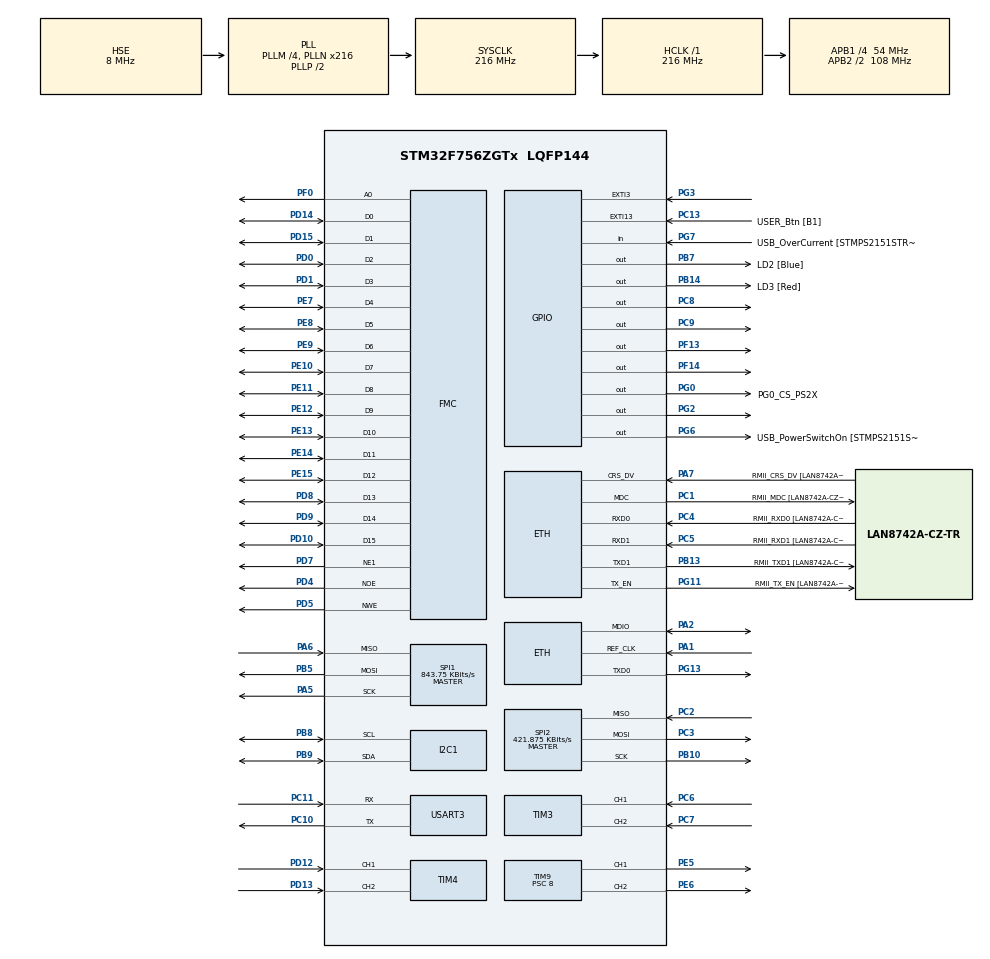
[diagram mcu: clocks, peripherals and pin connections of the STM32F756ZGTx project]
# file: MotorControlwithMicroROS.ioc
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CORTEX_M7.default_mode_Activation=1
Dma.Request0=USART3_RX
Dma.Request1=USART3_TX
Dma.USART3_RX.0.Direction=DMA_PERIPH_TO_MEMORY
Dma.USART3_RX.0.FIFOMode=DMA_FIFOMODE_DISABLE
Dma.USART3_RX.0.Instance=DMA1_Stream1
Dma.USART3_RX.0.MemDataAlignment=DMA_MDATAALIGN_BYTE
Dma.USART3_RX.0.MemInc=DMA_MINC_ENABLE
Dma.USART3_RX.0.Mode=DMA_CIRCULAR
Dma.USART3_RX.0.PeriphDataAlignment=DMA_PDATAALIGN_BYTE
Dma.USART3_RX.0.PeriphInc=DMA_PINC_DISABLE
Dma.USART3_RX.0.Priority=DMA_PRIORITY_VERY_HIGH
Dma.USART3_TX.1.Direction=DMA_MEMORY_TO_PERIPH
Dma.USART3_TX.1.FIFOMode=DMA_FIFOMODE_DISABLE
Dma.USART3_TX.1.Instance=DMA1_Stream3
Dma.USART3_TX.1.MemDataAlignment=DMA_MDATAALIGN_BYTE
Dma.USART3_TX.1.MemInc=DMA_MINC_ENABLE
Dma.USART3_TX.1.Mode=DMA_NORMAL
Dma.USART3_TX.1.PeriphDataAlignment=DMA_PDATAALIGN_BYTE
Dma.USART3_TX.1.PeriphInc=DMA_PINC_DISABLE
Dma.USART3_TX.1.Priority=DMA_PRIORITY_VERY_HIGH
ETH.ETH_RX_DESC_CNT=4
ETH.ETH_TX_DESC_CNT=4
ETH.MediaInterface=HAL_ETH_RMII_MODE
ETH.RxMode=ETH_RXINTERRUPT_MODE
FMC.AddressSetupTime1=1
FMC.BusTurnAroundDuration1=0
FMC.DataSetupTime1=5
FREERTOS.Tasks01=defaultTask,24,3000,StartDefaultTask,Default,NULL,Dynamic,NULL,NULL
FREERTOS.configTOTAL_HEAP_SIZE=81920
I2C1.Timing=0x20404768
LWIP.BSP.number=1
LWIP.IP_ADDRESS=192.168.004.050
LWIP.LWIP_DHCP=0
LWIP.LWIP_SO_RCVTIMEO=1
LWIP.LWIP_SO_SNDTIMEO=1
LWIP.LWIP_TCP=1
LWIP.MEMP_NUM_UDP_PCB=15
LWIP.NETMASK_ADDRESS=255.255.255.000
LWIP.Version=v2.1.2_Cube
LWIP0.BSP.STBoard=false
LWIP0.BSP.api=BSP_COMPONENT_DRIVER
LWIP0.BSP.component=LAN8742
LWIP0.BSP.instance=LAN8742
LWIP0.BSP.name=Driver_PHY
LWIP0.BSP.semaphore=S_LAN8742
LWIP0.BSP.solution=LAN8742
Mcu.Family=STM32F7
Mcu.Name=STM32F756ZGTx
Mcu.Package=LQFP144
NVIC.DMA1_Stream1_IRQn=true\:5\:0\:false\:false\:true\:true\:false\:true\:true
NVIC.DMA1_Stream3_IRQn=true\:5\:0\:false\:false\:true\:true\:false\:true\:true
NVIC.ETH_IRQn=true\:5\:0\:false\:false\:true\:true\:false\:true\:true
NVIC.PriorityGroup=NVIC_PRIORITYGROUP_4
NVIC.TIM6_DAC_IRQn=true\:15\:0\:false\:false\:true\:false\:false\:true\:true
NVIC.TimeBase=TIM6_DAC_IRQn
NVIC.TimeBaseIP=TIM6
NVIC.USART3_IRQn=true\:5\:0\:false\:false\:true\:true\:true\:true\:true
PA1.GPIO_Speed_Default_HIGH=GPIO_SPEED_FREQ_VERY_HIGH
PA1.Mode=RMII
PA1.Signal=ETH_REF_CLK
PA13.GPIO_Label=TMS
PA13.Mode=Serial_Wire
PA13.Signal=SYS_JTMS-SWDIO
PA14.GPIO_Label=TCK
PA14.Mode=Serial_Wire
PA14.Signal=SYS_JTCK-SWCLK
PA2.GPIO_Speed_Default_HIGH=GPIO_SPEED_FREQ_VERY_HIGH
PA2.Mode=RMII
PA2.Signal=ETH_MDIO
PA5.Mode=Full_Duplex_Master
PA5.Signal=SPI1_SCK
PA6.Mode=Full_Duplex_Master
PA6.Signal=SPI1_MISO
PA7.GPIO_Label=RMII_CRS_DV [LAN8742A-CZ-TR_CRS_DV]
PA7.GPIO_Speed_Default_HIGH=GPIO_SPEED_FREQ_VERY_HIGH
PA7.Mode=RMII
PA7.Signal=ETH_CRS_DV
PB10.Mode=Full_Duplex_Master
PB10.Signal=SPI2_SCK
PB13.GPIO_Label=RMII_TXD1 [LAN8742A-CZ-TR_TXD1]
PB13.GPIO_Speed_Default_HIGH=GPIO_SPEED_FREQ_VERY_HIGH
PB13.Mode=RMII
PB13.Signal=ETH_TXD1
PB14.GPIO_Label=LD3 [Red]
PB14.Signal=GPIO_Output
PB3.GPIO_Label=SW0
PB3.Signal=SYS_JTDO-SWO
PB5.Mode=Full_Duplex_Master
PB5.Signal=SPI1_MOSI
PB7.GPIO_Label=LD2 [Blue]
PB7.Signal=GPIO_Output
PB8.Mode=I2C
PB8.Signal=I2C1_SCL
PB9.Mode=I2C
PB9.Signal=I2C1_SDA
PC1.GPIO_Label=RMII_MDC [LAN8742A-CZ-TR_MDC]
PC1.GPIO_Speed_Default_HIGH=GPIO_SPEED_FREQ_VERY_HIGH
PC1.Mode=RMII
PC1.Signal=ETH_MDC
PC10.Mode=Asynchronous
PC10.Signal=USART3_TX
PC11.Mode=Asynchronous
PC11.Signal=USART3_RX
PC13.GPIO_Label=USER_Btn [B1]
PC13.Signal=GPXTI13
PC14/OSC32_IN.Mode=LSE-External-Oscillator
PC14/OSC32_IN.Signal=RCC_OSC32_IN
PC15/OSC32_OUT.Mode=LSE-External-Oscillator
PC15/OSC32_OUT.Signal=RCC_OSC32_OUT
PC2.Mode=Full_Duplex_Master
PC2.Signal=SPI2_MISO
PC3.Mode=Full_Duplex_Master
PC3.Signal=SPI2_MOSI
PC4.GPIO_Label=RMII_RXD0 [LAN8742A-CZ-TR_RXD0]
PC4.GPIO_Speed_Default_HIGH=GPIO_SPEED_FREQ_VERY_HIGH
PC4.Mode=RMII
PC4.Signal=ETH_RXD0
PC5.GPIO_Label=RMII_RXD1 [LAN8742A-CZ-TR_RXD1]
PC5.GPIO_Speed_Default_HIGH=GPIO_SPEED_FREQ_VERY_HIGH
PC5.Mode=RMII
PC5.Signal=ETH_RXD1
PC6.GPIO_ModeDefaultPP=GPIO_MODE_AF_PP
PC6.GPIO_PuPd=GPIO_NOPULL
PC6.Signal=S_TIM3_CH1
PC7.GPIO_ModeDefaultPP=GPIO_MODE_AF_PP
PC7.GPIO_PuPd=GPIO_NOPULL
PC7.Signal=S_TIM3_CH2
PC8.Signal=GPIO_Output
PC9.Signal=GPIO_Output
PD0.Signal=FMC_D2_DA2
PD1.Signal=FMC_D3_DA3
PD10.Signal=FMC_D15_DA15
PD12.Signal=S_TIM4_CH1
PD13.Signal=S_TIM4_CH2
PD14.Signal=FMC_D0_DA0
PD15.Signal=FMC_D1_DA1
PD4.Signal=FMC_NOE
PD5.Signal=FMC_NWE
PD7.Mode=NorPsramChipSelect1_1
PD7.Signal=FMC_NE1
PD8.Signal=FMC_D13_DA13
PD9.Signal=FMC_D14_DA14
PE10.Signal=FMC_D7_DA7
PE11.Signal=FMC_D8_DA8
PE12.Signal=FMC_D9_DA9
PE13.Signal=FMC_D10_DA10
PE14.Signal=FMC_D11_DA11
PE15.Signal=FMC_D12_DA12
PE5.Signal=S_TIM9_CH1
PE6.Signal=S_TIM9_CH2
PE7.Signal=FMC_D4_DA4
PE8.Signal=FMC_D5_DA5
PE9.Signal=FMC_D6_DA6
PF0.Signal=FMC_A0
PF13.Signal=GPIO_Output
PF14.Signal=GPIO_Output
PG0.GPIO_Label=PG0_CS_PS2X
PG0.GPIO_ModeDefaultOutputPP=GPIO_MODE_OUTPUT_PP
PG0.GPIO_Speed=GPIO_SPEED_FREQ_HIGH
PG0.PinState=GPIO_PIN_SET
PG0.Signal=GPIO_Output
PG11.GPIO_Label=RMII_TX_EN [LAN8742A-CZ-TR_TXEN]
PG11.GPIO_Speed_Default_HIGH=GPIO_SPEED_FREQ_VERY_HIGH
PG11.Mode=RMII
PG11.Signal=ETH_TX_EN
PG13.GPIO_Speed_Default_HIGH=GPIO_SPEED_FREQ_VERY_HIGH
PG13.Mode=RMII
PG13.Signal=ETH_TXD0
PG2.GPIO_Speed=GPIO_SPEED_FREQ_LOW
PG2.PinState=GPIO_PIN_SET
PG2.Signal=GPIO_Output
PG3.GPIO_ModeDefaultEXTI=GPIO_MODE_IT_FALLING
PG3.GPIO_PuPd=GPIO_PULLUP
PG3.Signal=GPXTI3
PG6.GPIO_Label=USB_PowerSwitchOn [STMPS2151STR_EN]
PG6.Signal=GPIO_Output
PG7.GPIO_Label=USB_OverCurrent [STMPS2151STR_FAULT]
PG7.Signal=GPIO_Input
PH0/OSC_IN.GPIO_Label=MCO [STM32F103CBT6_PA8]
PH0/OSC_IN.Mode=HSE-External-Oscillator
PH0/OSC_IN.Signal=RCC_OSC_IN
PH1/OSC_OUT.Mode=HSE-External-Oscillator
PH1/OSC_OUT.Signal=RCC_OSC_OUT
ProjectManager.HeapSize=0x200
ProjectManager.StackSize=0x400
ProjectManager.TargetToolchain=Makefile
RCC.48MHZClocksFreq_Value=24000000
RCC.AHBFreq_Value=216000000
RCC.APB1CLKDivider=RCC_HCLK_DIV4
RCC.APB1Freq_Value=54000000
RCC.APB1TimFreq_Value=108000000
RCC.APB2CLKDivider=RCC_HCLK_DIV2
RCC.APB2Freq_Value=108000000
RCC.APB2TimFreq_Value=216000000
RCC.CortexFreq_Value=216000000
RCC.HCLKFreq_Value=216000000
RCC.HSE_VALUE=8000000
RCC.HSI_VALUE=16000000
RCC.PLLM=4
RCC.PLLMUL=RCC_PLL_MUL9
RCC.PLLN=216
RCC.PLLQ=3
RCC.PLLSourceVirtual=RCC_PLLSOURCE_HSE
RCC.PRESCALERUSB=RCC_USBCLKSOURCE_PLL_DIV1_5
RCC.SYSCLKFreq_VALUE=216000000
RCC.SYSCLKSource=RCC_SYSCLKSOURCE_PLLCLK
RCC.SYSCLKSourceVirtual=RCC_SYSCLKSOURCE_PLLCLK
RCC.USBFreq_Value=144000000
RCC.VCOOutputFreq_Value=432000000
SH.FMC_A0.0=FMC_A0,A0_1
SH.FMC_D0_DA0.0=FMC_D0,16b-d1
SH.FMC_D10_DA10.0=FMC_D10,16b-d1
SH.FMC_D11_DA11.0=FMC_D11,16b-d1
SH.FMC_D12_DA12.0=FMC_D12,16b-d1
SH.FMC_D13_DA13.0=FMC_D13,16b-d1
SH.FMC_D14_DA14.0=FMC_D14,16b-d1
SH.FMC_D15_DA15.0=FMC_D15,16b-d1
SH.FMC_D1_DA1.0=FMC_D1,16b-d1
SH.FMC_D2_DA2.0=FMC_D2,16b-d1
SH.FMC_D3_DA3.0=FMC_D3,16b-d1
SH.FMC_D4_DA4.0=FMC_D4,16b-d1
SH.FMC_D5_DA5.0=FMC_D5,16b-d1
SH.FMC_D6_DA6.0=FMC_D6,16b-d1
SH.FMC_D7_DA7.0=FMC_D7,16b-d1
SH.FMC_D8_DA8.0=FMC_D8,16b-d1
SH.FMC_D9_DA9.0=FMC_D9,16b-d1
SH.FMC_NOE.0=FMC_NOE,Lcd1
SH.FMC_NWE.0=FMC_NWE,Lcd1
SH.S_TIM3_CH1.0=TIM3_CH1,Encoder_Interface
SH.S_TIM3_CH2.0=TIM3_CH2,Encoder_Interface
SH.S_TIM4_CH1.0=TIM4_CH1,Encoder_Interface
SH.S_TIM4_CH2.0=TIM4_CH2,Encoder_Interface
SH.S_TIM9_CH1.0=TIM9_CH1,PWM Generation1 CH1
SH.S_TIM9_CH2.0=TIM9_CH2,PWM Generation2 CH2
SPI1.BaudRatePrescaler=SPI_BAUDRATEPRESCALER_128
SPI1.CalculateBaudRate=843.75 KBits/s
SPI1.DataSize=SPI_DATASIZE_8BIT
SPI1.Direction=SPI_DIRECTION_2LINES
SPI1.Mode=SPI_MODE_MASTER
SPI1.VirtualType=VM_MASTER
SPI2.BaudRatePrescaler=SPI_BAUDRATEPRESCALER_128
SPI2.CLKPhase=SPI_PHASE_2EDGE
SPI2.CLKPolarity=SPI_POLARITY_HIGH
SPI2.CalculateBaudRate=421.875 KBits/s
SPI2.DataSize=SPI_DATASIZE_8BIT
SPI2.Direction=SPI_DIRECTION_2LINES
SPI2.FirstBit=SPI_FIRSTBIT_LSB
SPI2.Mode=SPI_MODE_MASTER
SPI2.VirtualType=VM_MASTER
TIM3.AutoReloadPreload=TIM_AUTORELOAD_PRELOAD_ENABLE
TIM3.EncoderMode=TIM_ENCODERMODE_TI12
TIM3.IC1Filter=6
TIM3.IC2Filter=6
TIM4.AutoReloadPreload=TIM_AUTORELOAD_PRELOAD_ENABLE
TIM4.EncoderMode=TIM_ENCODERMODE_TI12
TIM4.IC1Filter=6
TIM4.IC2Filter=6
TIM9.Channel-PWM\ Generation1\ CH1=TIM_CHANNEL_1
TIM9.Channel-PWM\ Generation2\ CH2=TIM_CHANNEL_2
TIM9.Period=1199
TIM9.Prescaler=8
USART3.VirtualMode-Asynchronous=VM_ASYNC
VP_FREERTOS_VS_CMSIS_V2.Mode=CMSIS_V2
VP_LWIP_VS_Enabled.Mode=Enabled
VP_SYS_VS_tim6.Mode=TIM6
VP_TIM9_VS_ClockSourceINT.Mode=Internal
board=NUCLEO-F756ZG

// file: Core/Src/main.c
/* USER CODE BEGIN Header */
/**
  ******************************************************************************
  * @file           : main.c
  * @brief          : Main program body
  ******************************************************************************
  * @attention
  *
  * Copyright (c) 2025 STMicroelectronics.
  * All rights reserved.
  *
  * This software is licensed under terms that can be found in the LICENSE file
  * in the root directory of this software component.
  * If no LICENSE file comes with this software, it is provided AS-IS.
  *
  ******************************************************************************
  */
/* USER CODE END Header */
#include "main.h"
#include "cmsis_os.h"
#include "dma.h"
#include "i2c.h"
#include "lwip.h"
#include "spi.h"
#include "tim.h"
#include "usart.h"
#include "gpio.h"
#include "fmc.h"

/* USER CODE BEGIN Includes */
#include "robot_params.h"
#include "encoder.h"
#include "motor.h"
#include "encoder_speed.h"
#include "pid.h"
#include "odometry.h"
#include "ili9341.h"
#include "xpt2046.h"
#include "touch_event.h"
#include "ps2xlib.h"
#include <stdarg.h>
#include <stdio.h>
#include <stdbool.h>

//#include "usb_otg_host.h"
/* USER CODE END Includes */

/* USER CODE BEGIN PTD */
#define min(a,b) (((a)<(b))?(a):(b))
/* USER CODE END PTD */

/* USER CODE BEGIN PD */
//ETH_HandleTypeDef heth;
/* USER CODE END PD */

void SystemClock_Config(void);
static void MPU_Config(void);
void MX_FREERTOS_Init(void);
/* USER CODE BEGIN PFP */
void demoLCD(int i);
void locLCD(void);
unsigned long testFillScreen();
unsigned long testText();
unsigned long testLines(uint16_t color);
unsigned long testFastLines(uint16_t color1, uint16_t color2);
unsigned long testRects(uint16_t color);
unsigned long testFilledRects(uint16_t color1, uint16_t color2);
unsigned long testFilledCircles(uint8_t radius, uint16_t color);
unsigned long testCircles(uint8_t radius, uint16_t color);
unsigned long testTriangles();
unsigned long testFilledTriangles();
unsigned long testRoundRects();
unsigned long testFilledRoundRects();
unsigned long testDrawImage();
/* USER CODE END PFP */

int main(void)
{

  /* MPU Configuration--------------------------------------------------------*/
  MPU_Config();

  /* MCU Configuration--------------------------------------------------------*/

  /* Reset of all peripherals, Initializes the Flash interface and the Systick. */
  HAL_Init();

  /* USER CODE BEGIN Init */
  //SCB_DisableDCache();
  /* USER CODE END Init */

  /* Configure the system clock */
  SystemClock_Config();

  /* Initialize all configured peripherals */
  MX_GPIO_Init();
  MX_DMA_Init();
  MX_I2C1_Init();
  MX_USART3_UART_Init();
  MX_TIM3_Init();
  MX_TIM9_Init();
  MX_FMC_Init();
  MX_SPI1_Init();
  MX_SPI2_Init();
  MX_TIM4_Init();
  /* USER CODE BEGIN 2 */
  //HAL_NVIC_DisableIRQ(TIM6_DAC_IRQn);  //tam dung ngat timer 6 de setup
  //MX_USB_OTG_FS_HCD_Init();
  //MX_USB_HOST_Init();
  //HAL_NVIC_EnableIRQ(TIM6_DAC_IRQn);   //bat lai ngat timer 6

  HAL_GPIO_WritePin(GPIOC, GPIO_PIN_8, GPIO_PIN_RESET); // RESET = 0
  HAL_Delay(10);
  HAL_GPIO_WritePin(GPIOC, GPIO_PIN_8, GPIO_PIN_SET);   // RESET = 1
  HAL_Delay(120);

  //Initialize touch event
  //Touch_Init_Lib();

  Encoder_Reset(ENCODER_1);
  Encoder_Reset(ENCODER_2);
  Encoder_Init();
  EncoderSpeed_Init();
  Motor_Init();

  //int32_t PID_sampletime = 5;

  PID(&PosPID1, &CurPos1, &PosPIDOut1, &DesiredPos1, Kp1, Ki1, Kd1, _PID_P_ON_E, _PID_CD_DIRECT);
  PID_SetMode(&PosPID1, _PID_MODE_AUTOMATIC);
  PID_SetSampleTime(&PosPID1, MOTORCONTROL_PERIOD_MS);
  PID_SetOutputLimits(&PosPID1, -MOTOR_SPEED_MAX, MOTOR_SPEED_MAX);

  PID(&PosPID2, &CurPos2, &PosPIDOut2, &DesiredPos2, Kp2, Ki2, Kd2, _PID_P_ON_E, _PID_CD_DIRECT);
  PID_SetMode(&PosPID2, _PID_MODE_AUTOMATIC);
  PID_SetSampleTime(&PosPID2, MOTORCONTROL_PERIOD_MS);
  PID_SetOutputLimits(&PosPID2, -MOTOR_SPEED_MAX, MOTOR_SPEED_MAX);

  PID(&SpeedPID1, &CurSpeed1, &SpeedPIDOut1, &DesiredSpeed1, Kp1, Ki1, Kd1, _PID_P_ON_E, _PID_CD_DIRECT);
  PID_SetMode(&SpeedPID1, _PID_MODE_AUTOMATIC);
  PID_SetSampleTime(&SpeedPID1, MOTORCONTROL_PERIOD_MS);
  PID_SetOutputLimits(&SpeedPID1, -MOTOR_SPEED_MAX, MOTOR_SPEED_MAX);

  PID(&SpeedPID2, &CurSpeed2, &SpeedPIDOut2, &DesiredSpeed2, Kp2, Ki2, Kd2, _PID_P_ON_E, _PID_CD_DIRECT);
  PID_SetMode(&SpeedPID2, _PID_MODE_AUTOMATIC);
  PID_SetSampleTime(&SpeedPID2, MOTORCONTROL_PERIOD_MS);
  PID_SetOutputLimits(&SpeedPID2, -MOTOR_SPEED_MAX, MOTOR_SPEED_MAX);

  PID_Init(&PosPID1); PID_Init(&PosPID2);
  PID_Init(&SpeedPID1); PID_Init(&SpeedPID2);

  //Here start to display LCD
  lcdInit();
  int i = 1;
  for (i=0;i<=0;i++)
  {
	  //demoLCD(i);
	  locLCD();

  }

//  const char test_msg[] = "USART2 VCP OK\r\n";
//  while (1)
//  {
//	  HAL_StatusTypeDef st = HAL_UART_Transmit(&huart2,
//	                                           (uint8_t*)test_msg,
//	                                           sizeof(test_msg)-1,
//	                                           10);
//
//    HAL_Delay(500);   // gửi mỗi 500 ms
//  }
  /* USER CODE END 2 */

  /* Init scheduler */
  osKernelInitialize();  /* Call init function for freertos objects (in cmsis_os2.c) */
  MX_FREERTOS_Init();

  /* Start scheduler */
  osKernelStart();

  /* We should never get here as control is now taken by the scheduler */

  /* Infinite loop */
  while (1)
  {

  }
}

void SystemClock_Config(void)
{
  RCC_OscInitTypeDef RCC_OscInitStruct = {0};
  RCC_ClkInitTypeDef RCC_ClkInitStruct = {0};

  /** Configure LSE Drive Capability
  */
  HAL_PWR_EnableBkUpAccess();

  /** Configure the main internal regulator output voltage
  */
  __HAL_RCC_PWR_CLK_ENABLE();
  __HAL_PWR_VOLTAGESCALING_CONFIG(PWR_REGULATOR_VOLTAGE_SCALE1);

  /** Initializes the RCC Oscillators according to the specified parameters
  * in the RCC_OscInitTypeDef structure.
  */
  RCC_OscInitStruct.OscillatorType = RCC_OSCILLATORTYPE_HSE;
  RCC_OscInitStruct.HSEState = RCC_HSE_ON;
  RCC_OscInitStruct.PLL.PLLState = RCC_PLL_ON;
  RCC_OscInitStruct.PLL.PLLSource = RCC_PLLSOURCE_HSE;
  RCC_OscInitStruct.PLL.PLLM = 4;
  RCC_OscInitStruct.PLL.PLLN = 216;
  RCC_OscInitStruct.PLL.PLLP = RCC_PLLP_DIV2;
  RCC_OscInitStruct.PLL.PLLQ = 3;
  if (HAL_RCC_OscConfig(&RCC_OscInitStruct) != HAL_OK)
  {
    Error_Handler();
  }

  /** Activate the Over-Drive mode
  */
  if (HAL_PWREx_EnableOverDrive() != HAL_OK)
  {
    Error_Handler();
  }

  /** Initializes the CPU, AHB and APB buses clocks
  */
  RCC_ClkInitStruct.ClockType = RCC_CLOCKTYPE_HCLK|RCC_CLOCKTYPE_SYSCLK
                              |RCC_CLOCKTYPE_PCLK1|RCC_CLOCKTYPE_PCLK2;
  RCC_ClkInitStruct.SYSCLKSource = RCC_SYSCLKSOURCE_PLLCLK;
  RCC_ClkInitStruct.AHBCLKDivider = RCC_SYSCLK_DIV1;
  RCC_ClkInitStruct.APB1CLKDivider = RCC_HCLK_DIV4;
  RCC_ClkInitStruct.APB2CLKDivider = RCC_HCLK_DIV2;

  if (HAL_RCC_ClockConfig(&RCC_ClkInitStruct, FLASH_LATENCY_7) != HAL_OK)
  {
    Error_Handler();
  }
}

/* USER CODE BEGIN 4 */
void MPU_Config(void)
{
  MPU_Region_InitTypeDef MPU_InitStruct = {0};

  HAL_MPU_Disable();

  // -------- Region0: default deny (giữ giống bạn) --------
  MPU_InitStruct.Enable           = MPU_REGION_ENABLE;
  MPU_InitStruct.Number           = MPU_REGION_NUMBER0;
  MPU_InitStruct.BaseAddress      = 0x00000000;
  MPU_InitStruct.Size             = MPU_REGION_SIZE_4GB;
  MPU_InitStruct.SubRegionDisable = 0x87; // như bạn
  MPU_InitStruct.TypeExtField     = MPU_TEX_LEVEL0;
  MPU_InitStruct.AccessPermission = MPU_REGION_NO_ACCESS;
  MPU_InitStruct.DisableExec      = MPU_INSTRUCTION_ACCESS_DISABLE;
  MPU_InitStruct.IsShareable      = MPU_ACCESS_SHAREABLE;
  MPU_InitStruct.IsCacheable      = MPU_ACCESS_NOT_CACHEABLE;
  MPU_InitStruct.IsBufferable     = MPU_ACCESS_NOT_BUFFERABLE;
  HAL_MPU_ConfigRegion(&MPU_InitStruct);

  // -------- Region1: allow FMC registers @0xA0000000 --------
  MPU_InitStruct.Enable           = MPU_REGION_ENABLE;
  MPU_InitStruct.Number           = MPU_REGION_NUMBER1;
  MPU_InitStruct.BaseAddress      = 0xA0000000;
  MPU_InitStruct.Size             = MPU_REGION_SIZE_1MB;   // đủ cho FMC regs
  MPU_InitStruct.SubRegionDisable = 0x00;
  MPU_InitStruct.TypeExtField     = MPU_TEX_LEVEL0;
  MPU_InitStruct.AccessPermission = MPU_REGION_FULL_ACCESS;
  MPU_InitStruct.DisableExec      = MPU_INSTRUCTION_ACCESS_DISABLE;
  MPU_InitStruct.IsShareable      = MPU_ACCESS_SHAREABLE;
  MPU_InitStruct.IsCacheable      = MPU_ACCESS_NOT_CACHEABLE;
  MPU_InitStruct.IsBufferable     = MPU_ACCESS_BUFFERABLE; // peripheral/device
  HAL_MPU_ConfigRegion(&MPU_InitStruct);

  // -------- Region2: allow FMC Bank1 mapped @0x60000000 (LCD) --------
  MPU_InitStruct.Enable           = MPU_REGION_ENABLE;
  MPU_InitStruct.Number           = MPU_REGION_NUMBER2;
  MPU_InitStruct.BaseAddress      = 0x60000000;
  MPU_InitStruct.Size             = MPU_REGION_SIZE_64MB;  // Bank1 window (thường dùng)
  MPU_InitStruct.SubRegionDisable = 0x00;
  MPU_InitStruct.TypeExtField     = MPU_TEX_LEVEL0;
  MPU_InitStruct.AccessPermission = MPU_REGION_FULL_ACCESS;
  MPU_InitStruct.DisableExec      = MPU_INSTRUCTION_ACCESS_DISABLE;
  MPU_InitStruct.IsShareable      = MPU_ACCESS_SHAREABLE;
  MPU_InitStruct.IsCacheable      = MPU_ACCESS_NOT_CACHEABLE;
  MPU_InitStruct.IsBufferable     = MPU_ACCESS_BUFFERABLE;
  HAL_MPU_ConfigRegion(&MPU_InitStruct);

  HAL_MPU_Enable(MPU_PRIVILEGED_DEFAULT);
}

void demoLCD(int i)
{
	lcdSetOrientation(i % 4);

	uint32_t t = testFillScreen();
	lcdSetTextFont(&Font16);
	lcdSetCursor(0, lcdGetHeight() - lcdGetTextFont()->Height - 1);
	lcdSetTextColor(COLOR_WHITE, COLOR_BLACK);
	lcdPrintf("Time: %4lu ms", t);
	HAL_Delay(2000);

	t = HAL_GetTick();
	lcdTest();
	lcdSetTextFont(&Font16);
	lcdSetCursor(0, lcdGetHeight() - lcdGetTextFont()->Height - 1);
	lcdSetTextColor(COLOR_WHITE, COLOR_BLACK);
	lcdPrintf("Time: %4lu ms", HAL_GetTick() - t);
	HAL_Delay(2000);

	t = testText();
	lcdSetTextFont(&Font16);
	lcdSetCursor(0, lcdGetHeight() - lcdGetTextFont()->Height - 1);
	lcdSetTextColor(COLOR_WHITE, COLOR_BLACK);
	lcdPrintf("Time: %4lu ms", t);
	HAL_Delay(2000);

	lcdSetTextFont(&Font16);
	lcdSetCursor(0, lcdGetHeight() - lcdGetTextFont()->Height - 1);
	lcdSetTextColor(COLOR_WHITE, COLOR_BLACK);
	lcdPrintf("Time: %4lu ms", testLines(COLOR_CYAN));
	HAL_Delay(2000);

	lcdSetTextFont(&Font16);
	lcdSetCursor(0, lcdGetHeight() - lcdGetTextFont()->Height - 1);
	lcdSetTextColor(COLOR_WHITE, COLOR_BLACK);
	lcdPrintf("Time: %4lu ms", testFastLines(COLOR_RED, COLOR_BLUE));
	HAL_Delay(2000);

	lcdSetTextFont(&Font16);
	lcdSetCursor(0, lcdGetHeight() - lcdGetTextFont()->Height - 1);
	lcdSetTextColor(COLOR_WHITE, COLOR_BLACK);
	lcdPrintf("Time: %4lu ms", testRects(COLOR_GREEN));
	HAL_Delay(2000);

	lcdSetTextFont(&Font16);
	lcdSetCursor(0, lcdGetHeight() - lcdGetTextFont()->Height - 1);
	lcdSetTextColor(COLOR_WHITE, COLOR_BLACK);
	lcdPrintf("Time: %4lu ms", testFilledRects(COLOR_YELLOW, COLOR_MAGENTA));
	HAL_Delay(2000);

	lcdSetTextFont(&Font16);
	lcdSetCursor(0, lcdGetHeight() - lcdGetTextFont()->Height - 1);
	lcdSetTextColor(COLOR_WHITE, COLOR_BLACK);
	lcdPrintf("Time: %4lu ms", testFilledCircles(10, COLOR_MAGENTA));
	HAL_Delay(2000);

	lcdSetTextFont(&Font16);
	lcdSetCursor(0, lcdGetHeight() - lcdGetTextFont()->Height - 1);
	lcdSetTextColor(COLOR_WHITE, COLOR_BLACK);
	lcdPrintf("Time: %4lu ms", testCircles(10, COLOR_WHITE));
	HAL_Delay(2000);

	lcdSetTextFont(&Font16);
	lcdSetCursor(0, lcdGetHeight() - lcdGetTextFont()->Height - 1);
	lcdSetTextColor(COLOR_WHITE, COLOR_BLACK);
	lcdPrintf("Time: %4lu ms", testTriangles());
	HAL_Delay(2000);

	lcdSetTextFont(&Font16);
	lcdSetCursor(0, lcdGetHeight() - lcdGetTextFont()->Height - 1);
	lcdSetTextColor(COLOR_WHITE, COLOR_BLACK);
	lcdPrintf("Time: %4lu ms", testFilledTriangles());
	HAL_Delay(2000);

	lcdSetTextFont(&Font16);
	lcdSetCursor(0, lcdGetHeight() - lcdGetTextFont()->Height - 1);
	lcdSetTextColor(COLOR_WHITE, COLOR_BLACK);
	lcdPrintf("Time: %4lu ms", testRoundRects());
	HAL_Delay(2000);

	lcdSetTextFont(&Font16);
	lcdSetCursor(0, lcdGetHeight() - lcdGetTextFont()->Height - 1);
	lcdSetTextColor(COLOR_WHITE, COLOR_BLACK);
	lcdPrintf("Time: %4lu ms", testFilledRoundRects());
	HAL_Delay(2000);

	lcdSetTextFont(&Font16);
	lcdSetCursor(0, lcdGetHeight() - lcdGetTextFont()->Height - 1);
	lcdSetTextColor(COLOR_WHITE, COLOR_BLACK);
	lcdPrintf("Time: %4lu ms", testDrawImage());
	HAL_Delay(2000);
}

typedef struct { uint16_t x,y,w,h; } Rect_t;

static Rect_t g_val_pwm1, g_val_pwm2, g_val_enc1, g_val_enc2;
static Rect_t g_val_v1, g_val_v2;
static Rect_t g_val_x, g_val_y, g_val_yaw;

static uint16_t g_charW = 8, g_fontH = 12, g_pad = 6;

void locLCD(void)
{
    lcdSetOrientation(LCD_ORIENTATION_LANDSCAPE);
    lcdFillRGB(COLOR_BLACK);
    lcdSetTextFont(&Font12);

    uint16_t W = lcdGetWidth();
    uint16_t H = lcdGetHeight();

    uint16_t fontH = lcdGetTextFont()->Height;
    uint16_t charW = lcdGetTextFont()->Width;   // nếu lỗi -> đổi thành 8

    // ===== Grid =====
    uint16_t M  = 6;
    uint16_t GX = M;
    uint16_t GY = 22;
    uint16_t GW = W - 2*M;
    uint16_t GH = H - GY - M;

    uint16_t CW = GW / 3;
    uint16_t RH = GH / 4;
    uint16_t P  = 6;
    g_fontH = fontH;
    g_charW = (charW == 0) ? 8 : charW;
    g_pad   = P;

    #define STORE_VALUE_RECT(_rect, cx, cy, cw, ch) do {                          \
        int16_t _y0 = (int16_t)(cy) + (int16_t)(((ch) - 2*(int16_t)fontH)/2);     \
        if (_y0 < (int16_t)(cy)+P) _y0 = (int16_t)(cy)+P;                         \
        (_rect).x = (uint16_t)((cx) + 1);                                         \
        (_rect).y = (uint16_t)(_y0 + (int16_t)fontH);                             \
        (_rect).w = (uint16_t)((cw) - 2);                                         \
        (_rect).h = (uint16_t)(fontH);                                            \
    } while(0)
    // ===== Header =====
    lcdSetTextColor(COLOR_YELLOW, COLOR_BLACK);
    lcdSetCursor(M, 4);
    lcdPrintf("Robomango Zackon");

    // ===== Draw grid =====
    lcdSetTextColor(COLOR_WHITE, COLOR_BLACK);
    lcdDrawRect(GX, GY, GW, GH, COLOR_WHITE);
    lcdDrawVLine(GX + CW,   GY, GY + GH, COLOR_WHITE);
    lcdDrawVLine(GX + 2*CW, GY, GY + GH, COLOR_WHITE);
    for (int r = 1; r < 4; r++)
        lcdDrawHLine(GX, GX + GW, GY + r*RH, COLOR_WHITE);

    #define CELL_X(c) (GX + (c)*CW)
    #define CELL_Y(r) (GY + (r)*RH)
    #define MAX_CHARS(_w)  ((int)(((_w) - 2*P) / charW))

    // ===== In 2 dòng, CẢ 2 dòng đều căn giữa + clip không tràn =====
    #define PRINT_2LINES_CENTER(cx,cy,cw,ch,l1,l2,color,bg) do {           \
        int m = MAX_CHARS(cw); if (m < 1) m = 1;                           \
        int len1 = (int)strlen(l1); if (len1 > m) len1 = m;                \
        int len2 = (int)strlen(l2); if (len2 > m) len2 = m;                \
        int w1 = len1 * (int)charW;                                        \
        int w2 = len2 * (int)charW;                                        \
        int wMax = (w1 > w2) ? w1 : w2;                                    \
        int16_t x = (int16_t)(cx) + (int16_t)((cw) - wMax)/2;              \
        int16_t y = (int16_t)(cy) + (int16_t)((ch) - 2*(int16_t)fontH)/2;  \
        if (x < (int16_t)(cx)+P) x = (int16_t)(cx)+P;                      \
        if (y < (int16_t)(cy)+P) y = (int16_t)(cy)+P;                      \
        lcdSetTextColor(color, bg);                                        \
        lcdSetCursor((unsigned short)x, (unsigned short)y);                \
        lcdPrintf("%.*s", len1, l1);                                       \
        lcdSetCursor((unsigned short)x, (unsigned short)(y + fontH));      \
        lcdPrintf("%.*s", len2, l2);                                       \
    } while(0)

    // ===== Button: 1 dòng căn giữa + clip =====
    #define PRINT_CENTER_1LINE(cx,cy,cw,ch,text,color,bg) do {             \
        int m = MAX_CHARS(cw); if (m < 1) m = 1;                           \
        int len = (int)strlen(text); if (len > m) len = m;                 \
        int16_t x = (int16_t)(cx) + (int16_t)((cw) - len*(int)charW)/2;    \
        int16_t y = (int16_t)(cy) + (int16_t)((ch) - (int16_t)fontH)/2 + 1;\
        if (x < (int16_t)(cx)+P) x = (int16_t)(cx)+P;                      \
        if (y < (int16_t)(cy)+P) y = (int16_t)(cy)+P;                      \
        lcdSetTextColor(color, bg);                                        \
        lcdSetCursor((unsigned short)x, (unsigned short)y);                \
        lcdPrintf("%.*s", len, text);                                      \
    } while(0)

    // ===== Cột 1 (tất cả CENTER) =====
    PRINT_2LINES_CENTER(CELL_X(0), CELL_Y(0), CW, RH, "PWM1", "0.0",  COLOR_CYAN, COLOR_BLACK);
    STORE_VALUE_RECT(g_val_pwm1, CELL_X(0), CELL_Y(0), CW, RH);

    PRINT_2LINES_CENTER(CELL_X(0), CELL_Y(1), CW, RH, "PWM2", "0.0",  COLOR_CYAN, COLOR_BLACK);
    STORE_VALUE_RECT(g_val_pwm2, CELL_X(0), CELL_Y(1), CW, RH);

    PRINT_2LINES_CENTER(CELL_X(0), CELL_Y(2), CW, RH, "Enc1", "0.0", COLOR_CYAN, COLOR_BLACK);
    STORE_VALUE_RECT(g_val_enc1, CELL_X(0), CELL_Y(2), CW, RH);

    PRINT_2LINES_CENTER(CELL_X(0), CELL_Y(3), CW, RH, "Enc2", "0.0", COLOR_CYAN, COLOR_BLACK);
    STORE_VALUE_RECT(g_val_enc2, CELL_X(0), CELL_Y(3), CW, RH);

    // ===== Cột 2 =====
    PRINT_2LINES_CENTER(CELL_X(1), CELL_Y(0), CW, RH, "V1", "0.0", COLOR_CYAN, COLOR_BLACK);
    STORE_VALUE_RECT(g_val_v1, CELL_X(1), CELL_Y(0), CW, RH);

    PRINT_2LINES_CENTER(CELL_X(1), CELL_Y(1), CW, RH, "V2", "0.0", COLOR_CYAN, COLOR_BLACK);
    STORE_VALUE_RECT(g_val_v2, CELL_X(1), CELL_Y(1), CW, RH);

    // Button Figure
    {
        uint16_t bx = CELL_X(1)+4, by = CELL_Y(2)+4;
        uint16_t bw = CW-8, bh = RH-8;
        lcdFillRect(bx, by, bw, bh, COLOR_DARKGREY);
        lcdDrawRect(bx, by, bw, bh, COLOR_WHITE);
        PRINT_CENTER_1LINE(bx, by, bw, bh, "Figure", COLOR_DARKGREY, COLOR_DARKGREY);
    }

    // Button Controller
    {
        uint16_t bx = CELL_X(1)+4, by = CELL_Y(3)+4;
        uint16_t bw = CW-8, bh = RH-8;
        lcdFillRect(bx, by, bw, bh, COLOR_DARKGREY);
        lcdDrawRect(bx, by, bw, bh, COLOR_WHITE);
        PRINT_CENTER_1LINE(bx, by, bw, bh, "Controller", COLOR_WHITE, COLOR_DARKGREY);
    }

    // ===== Cột 3 =====
    PRINT_2LINES_CENTER(CELL_X(2), CELL_Y(0), CW, RH, "Odom X", "0.0", COLOR_CYAN, COLOR_BLACK);
    STORE_VALUE_RECT(g_val_x, CELL_X(2), CELL_Y(0), CW, RH);

    PRINT_2LINES_CENTER(CELL_X(2), CELL_Y(1), CW, RH, "Odom Y", "0.0", COLOR_CYAN, COLOR_BLACK);
    STORE_VALUE_RECT(g_val_y, CELL_X(2), CELL_Y(1), CW, RH);

    PRINT_2LINES_CENTER(CELL_X(2), CELL_Y(2), CW, RH, "Yaw",   "0.0", COLOR_CYAN, COLOR_BLACK);
    STORE_VALUE_RECT(g_val_yaw, CELL_X(2), CELL_Y(2), CW, RH);

    // Button Setting PID
    {
        uint16_t bx = CELL_X(2)+4, by = CELL_Y(3)+4;
        uint16_t bw = CW-8, bh = RH-8;
        lcdFillRect(bx, by, bw, bh, COLOR_DARKGREY);
        lcdDrawRect(bx, by, bw, bh, COLOR_WHITE);
        PRINT_CENTER_1LINE(bx, by, bw, bh, "Setting PID", COLOR_WHITE, COLOR_DARKGREY);
    }

    #undef PRINT_CENTER_1LINE
    #undef PRINT_2LINES_CENTER
    #undef MAX_CHARS
    #undef CELL_X
    #undef CELL_Y
	#undef STORE_VALUE_RECT

}

//static void drawValueInRect(const Rect_t* r, const char* val, uint16_t color, uint16_t bg)
//{
//    // clear đúng 1 dòng value
//    lcdFillRect(r->x, r->y, r->w, r->h, bg);
//
//    int maxChars = (int)((r->w - 2*g_pad) / g_charW);
//    if (maxChars < 1) maxChars = 1;
//
//    int len = (int)strlen(val);
//    if (len > maxChars) len = maxChars;
//
//    int16_t x = (int16_t)r->x + (int16_t)((r->w - len*(int)g_charW)/2);
//    int16_t y = (int16_t)r->y;
//
//    lcdSetTextColor(color, bg);
//    lcdSetCursor((unsigned short)x, (unsigned short)y);
//    lcdPrintf("%.*s", len, val);
//}

unsigned long testFillScreen()
{
	unsigned long start = HAL_GetTick(), t = 0;
	lcdFillRGB(COLOR_BLACK);
	t += HAL_GetTick() - start;
	lcdSetCursor(0, 0);
	lcdSetTextFont(&Font24);
	lcdSetTextColor(COLOR_WHITE, COLOR_BLACK);
	lcdPrintf("BLACK");
	HAL_Delay(1000);
	start = HAL_GetTick();
	lcdFillRGB(COLOR_RED);
	t += HAL_GetTick() - start;
	lcdSetCursor(0, 0);
	lcdSetTextFont(&Font24);
	lcdSetTextColor(COLOR_WHITE, COLOR_BLACK);
	lcdPrintf("RED");
	HAL_Delay(1000);
	start = HAL_GetTick();
	lcdFillRGB(COLOR_GREEN);
	t += HAL_GetTick() - start;
	lcdSetCursor(0, 0);
	lcdSetTextFont(&Font24);
	lcdSetTextColor(COLOR_WHITE, COLOR_BLACK);
	lcdPrintf("GREEN");
	HAL_Delay(1000);
	start = HAL_GetTick();
	lcdFillRGB(COLOR_BLUE);
	t += HAL_GetTick() - start;
	lcdSetCursor(0, 0);
	lcdSetTextFont(&Font24);
	lcdSetTextColor(COLOR_WHITE, COLOR_BLACK);
	lcdPrintf("BLUE");
	HAL_Delay(1000);
	start = HAL_GetTick();
	lcdFillRGB(COLOR_BLACK);
	return t += HAL_GetTick() - start;
}

	unsigned long testText()
	{
		lcdFillRGB(COLOR_BLACK);
		unsigned long start = HAL_GetTick();
		lcdSetCursor(0, 0);
		lcdSetTextColor(COLOR_WHITE, COLOR_BLACK);
		lcdSetTextFont(&Font8);
		lcdPrintf("Hello World!\r\n");
		lcdSetTextColor(COLOR_YELLOW, COLOR_BLACK);
		lcdSetTextFont(&Font12);
		lcdPrintf("%i\r\n", 1234567890);
		lcdSetTextColor(COLOR_RED, COLOR_BLACK);
		lcdSetTextFont(&Font12);
		lcdPrintf("%#X\r\n", 0xDEADBEEF);
		lcdPrintf("\r\n");
		lcdSetTextColor(COLOR_GREEN, COLOR_BLACK);
		lcdSetTextFont(&Font20);
		lcdPrintf("Groop\r\n");
		lcdSetTextFont(&Font12);
		lcdPrintf("I implore thee,\r\n");
		lcdSetTextFont(&Font12);
		lcdPrintf("my foonting turlingdromes.\r\n");
		lcdPrintf("And hooptiously drangle me\r\n");
		lcdPrintf("with crinkly bindlewurdles,\r\n");
		lcdPrintf("Or I will rend thee\r\n");
		lcdPrintf("in the gobberwarts\r\n");
		lcdPrintf("with my blurglecruncheon,\r\n");
		lcdPrintf("see if I don't!\r\n");
		return HAL_GetTick() - start;
	}

unsigned long testLines(uint16_t color)
{
  unsigned long start, t;
  int           x1, y1, x2, y2,
                w = lcdGetWidth(),
                h = lcdGetHeight();

  lcdFillRGB(COLOR_BLACK);

  x1 = y1 = 0;
  y2    = h - 1;
  start = HAL_GetTick();
  for(x2 = 0; x2 < w; x2 += 6) lcdDrawLine(x1, y1, x2, y2, color);
  x2 = w - 1;
  for(y2 = 0; y2 < h; y2 += 6) lcdDrawLine(x1, y1, x2, y2, color);
  t = HAL_GetTick() - start; // fillScreen doesn't count against timing

  HAL_Delay(1000);
  lcdFillRGB(COLOR_BLACK);

  x1 = w - 1;
  y1 = 0;
  y2 = h - 1;

  start = HAL_GetTick();

  for(x2 = 0; x2 < w; x2 += 6) lcdDrawLine(x1, y1, x2, y2, color);
  x2 = 0;
  for(y2 = 0; y2 < h; y2 += 6) lcdDrawLine(x1, y1, x2, y2, color);
  t += HAL_GetTick() - start;

  HAL_Delay(1000);
  lcdFillRGB(COLOR_BLACK);

  x1 = 0;
  y1 = h - 1;
  y2 = 0;
  start = HAL_GetTick();

  for(x2 = 0; x2 < w; x2 += 6) lcdDrawLine(x1, y1, x2, y2, color);
  x2 = w - 1;
  for(y2 = 0; y2 < h; y2 += 6) lcdDrawLine(x1, y1, x2, y2, color);
  t += HAL_GetTick() - start;

  HAL_Delay(1000);
  lcdFillRGB(COLOR_BLACK);

  x1 = w - 1;
  y1 = h - 1;
  y2 = 0;

  start = HAL_GetTick();

  for(x2 = 0; x2 < w; x2 += 6) lcdDrawLine(x1, y1, x2, y2, color);
  x2 = 0;
  for(y2 = 0; y2 < h; y2 += 6) lcdDrawLine(x1, y1, x2, y2, color);

  return t += HAL_GetTick() - start;
}

unsigned long testFastLines(uint16_t color1, uint16_t color2)
{
  unsigned long start;
  int x, y, w = lcdGetWidth(), h = lcdGetHeight();

  lcdFillRGB(COLOR_BLACK);
  start = HAL_GetTick();
  for(y = 0; y < h; y += 5) lcdDrawHLine(0, w, y, color1);
  for(x = 0; x < w; x += 5) lcdDrawVLine(x, 0, h, color2);

  return HAL_GetTick() - start;
}

unsigned long testRects(uint16_t color)
{
  unsigned long start;
  int n, i, i2,
      cx = lcdGetWidth()  / 2,
      cy = lcdGetHeight() / 2;

  lcdFillRGB(COLOR_BLACK);
  n = min(lcdGetWidth(), lcdGetHeight());
  start = HAL_GetTick();
  for(i = 2; i < n; i += 6)
  {
    i2 = i / 2;
    lcdDrawRect(cx - i2, cy - i2, i, i, color);
  }

  return HAL_GetTick() - start;
}

unsigned long testFilledRects(uint16_t color1, uint16_t color2)
{
  unsigned long start, t = 0;
  int n, i, i2,
      cx = lcdGetWidth() / 2 - 1,
      cy = lcdGetHeight() / 2 - 1;

  lcdFillRGB(COLOR_BLACK);
  n = min(lcdGetWidth(), lcdGetHeight());

  for(i = n; i > 0; i -= 6)
  {
    i2 = i / 2;
    start = HAL_GetTick();
    lcdFillRect(cx-i2, cy-i2, i, i, color1);
    t    += HAL_GetTick() - start;
    // Outlines are not included in timing results
    lcdDrawRect(cx-i2, cy-i2, i, i, color1);
  }

  return t;
}

unsigned long testFilledCircles(uint8_t radius, uint16_t color)
{
  unsigned long start;
  int x, y, w = lcdGetWidth(), h = lcdGetHeight(), r2 = radius * 2;

  lcdFillRGB(COLOR_BLACK);
  start = HAL_GetTick();
  for(x = radius; x < w; x += r2)
  {
    for(y = radius; y < h; y += r2)
    {
      lcdFillCircle(x, y, radius, color);
    }
  }

  return HAL_GetTick() - start;
}

unsigned long testCircles(uint8_t radius, uint16_t color)
{
  unsigned long start;
  int x, y, r2 = radius * 2,
      w = lcdGetWidth()  + radius,
      h = lcdGetHeight() + radius;

  // Screen is not cleared for this one -- this is
  // intentional and does not affect the reported time.
  start = HAL_GetTick();
  for(x = 0; x < w; x += r2)
  {
    for(y = 0; y < h; y += r2)
    {
      lcdDrawCircle(x, y, radius, color);
    }
  }

  return HAL_GetTick() - start;
}

unsigned long testTriangles()
{
  unsigned long start;
  int n, i, cx = lcdGetWidth() / 2 - 1,
            cy = lcdGetHeight() / 2 - 1;

  lcdFillRGB(COLOR_BLACK);
  n = min(cx, cy);
  start = HAL_GetTick();
  for(i = 0; i < n; i += 5)
  {
    lcdDrawTriangle(
      cx    , cy - i, // peak
      cx - i, cy + i, // bottom left
      cx + i, cy + i, // bottom right
      lcdColor565(i, i, i));
  }

  return HAL_GetTick() - start;
}

unsigned long testFilledTriangles()
{
  unsigned long start, t = 0;
  int i, cx = lcdGetWidth() / 2 - 1,
         cy = lcdGetHeight() / 2 - 1;

  lcdFillRGB(COLOR_BLACK);
  for(i = min(cx, cy); i > 10; i -= 5)
  {
    start = HAL_GetTick();
    lcdFillTriangle(cx, cy - i, cx - i, cy + i, cx + i, cy + i, lcdColor565(0, i*10, i*10));
    t += HAL_GetTick() - start;
    lcdFillTriangle(cx, cy - i, cx - i, cy + i, cx + i, cy + i, lcdColor565(i*10, i*10, 0));
  }

  return t;
}

unsigned long testRoundRects()
{
  unsigned long start;
  int w, i, i2,
      cx = lcdGetWidth() / 2 - 1,
      cy = lcdGetHeight() / 2 - 1;

  lcdFillRGB(COLOR_BLACK);
  w = lcdGetWidth(), lcdGetHeight();
  start = HAL_GetTick();
  for(i = 0; i < w; i += 6)
  {
    i2 = i / 2;
    lcdDrawRoundRect(cx-i2, cy-i2, i, i, i/8, lcdColor565(i, 0, 0));
  }

  return HAL_GetTick() - start;
}

unsigned long testFilledRoundRects()
{
  unsigned long start;
  int i, i2,
      cx = lcdGetWidth()  / 2 - 1,
      cy = lcdGetHeight() / 2 - 1;

  lcdFillRGB(COLOR_BLACK);
  start = HAL_GetTick();
  for(i = min(lcdGetWidth(), lcdGetHeight()); i > 20; i -=6 )
  {
    i2 = i / 2;
    lcdFillRoundRect(cx - i2, cy - i2, i, i, i / 8, lcdColor565(0, i, 0));
  }

  return HAL_GetTick() - start;
}

unsigned long testDrawImage()
{
	unsigned long start;

	lcdFillRGB(COLOR_BLACK);
	start = HAL_GetTick();
	if (lcdGetOrientation() == LCD_ORIENTATION_LANDSCAPE || lcdGetOrientation() == LCD_ORIENTATION_LANDSCAPE_MIRROR)
	{
		lcdDrawImage((lcdGetWidth() - bmSTLogo.xSize) / 2, 0, &bmSTLogo);
	}
	else
	{
		lcdDrawImage(0, (lcdGetHeight() - bmSTLogo.ySize) / 2, &bmSTLogo);
	}
	return HAL_GetTick() - start;
}
/* USER CODE END 4 */

void HAL_TIM_PeriodElapsedCallback(TIM_HandleTypeDef *htim)
{
  if (htim->Instance == TIM6)
  {
    HAL_IncTick();
  }
}

void Error_Handler(void)
{
  __disable_irq();
  while (1)
  {
  }
}

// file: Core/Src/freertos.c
/* USER CODE BEGIN Header */
/**
  ******************************************************************************
  * File Name          : freertos.c
  * Description        : Code for freertos applications
  ******************************************************************************
  * @attention
  *
  * Copyright (c) 2025 STMicroelectronics.
  * All rights reserved.
  *
  * This software is licensed under terms that can be found in the LICENSE file
  * in the root directory of this software component.
  * If no LICENSE file comes with this software, it is provided AS-IS.
  *
  ******************************************************************************
  */
/* USER CODE END Header */

#include "FreeRTOS.h"
#include "task.h"
#include "main.h"
#include "cmsis_os.h"

/* USER CODE BEGIN Includes */
#include <stdio.h>
#include <math.h>
#include "usart.h"
#include "robot_params.h"
#include "encoder.h"
#include "motor.h"
#include "motion_profile.h"
#include "encoder_speed.h"
#include "pid.h"
#include "odometry.h"
#include "semphr.h"
#include "touch_rtos.h"
#include "spi.h"
#include "touch_event.h"
#include "xpt2046.h"
#include "ps2xlib.h"
#include "ili9341.h"
#include "ui_screen.h"
#include "lwip/netif.h"
#include "lwip/ip4_addr.h"
#include "ethernetif.h"

#include <rcl/rcl.h>
#include <rcl/error_handling.h>
#include <rclc/rclc.h>
#include <rclc/executor.h>
#include <uxr/client/transport.h>
#include <rmw_microxrcedds_c/config.h>
#include <rmw_microros/rmw_microros.h>
#include <std_msgs/msg/int32.h>

#include <nav_msgs/msg/odometry.h>
#include <geometry_msgs/msg/quaternion.h>
#include <geometry_msgs/msg/vector3.h>
#include <geometry_msgs/msg/pose.h>
#include <geometry_msgs/msg/twist.h>
#include <std_msgs/msg/float64_multi_array.h>
#include <rosidl_runtime_c/string_functions.h>

static rcl_publisher_t odom_pub;
static nav_msgs__msg__Odometry odom_msg;

static bool g_odom_pub_initialized = false;
static bool g_odom_msg_initialized = false;

static volatile bool g_microros_ready = false;     // entities created and session ok
static volatile bool g_microros_run   = false;     // allow tasks to run
static volatile uint32_t g_odom_period_ms = 20;    // 50Hz default
static uint32_t odom_pub_fail_streak = 0;

//typedef enum
//{
//  MICROROS_WAIT_NET = 0,
//  MICROROS_WAIT_AGENT,
//  MICROROS_CREATE_SESSION,
//  MICROROS_RUN,
//  MICROROS_RECONNECT
//} microros_state_t;

// =========================
// Global micro-ROS objects
// =========================
static rcl_allocator_t g_allocator;
static rclc_support_t g_support;
static rcl_node_t g_node;
static rcl_subscription_t g_sub_cmdvel;
static rclc_executor_t g_executor;
static geometry_msgs__msg__Twist g_msg_cmdvel;

// Trạng thái lifecycle của các micro-ROS entities
static bool g_support_initialized = false;
static bool g_node_initialized = false;
static bool g_sub_cmdvel_initialized = false;
static bool g_executor_initialized = false;

// =========================
// CMSIS-RTOS v2 handles
// =========================
static osMutexId_t g_uros_mutex = NULL;
static osThreadId_t g_rx_task_handle = NULL;
static osThreadId_t g_odom_task_handle = NULL;

// =========================
// Shared flags
// =========================
volatile bool g_uros_connected = false;
volatile bool g_request_reconnect = false;

// =========================
// Debug
// =========================
volatile uint32_t dbg_rx_spin_err_cnt = 0;
volatile uint32_t dbg_pub_odom_cnt = 0;
volatile uint32_t dbg_manager_reconnect_cnt = 0;
volatile uint32_t dbg_eth_recovery_cnt = 0;
//----------------------------------------

volatile uint32_t dbg_cmd_cb_count = 0;
volatile uint32_t dbg_last_cmdvel_ms = 0;
volatile uint32_t dbg_cmd_gap_ms = 0;
volatile uint32_t dbg_cmd_gap_max_ms = 0;
volatile uint32_t dbg_cmd_gap_over_500ms = 0;

volatile float dbg_last_cmd_v = 0.0f;
volatile float dbg_last_cmd_w = 0.0f;
//------------------------------------------------------

volatile uint32_t last_cmdvel_ms = 0;
volatile uint8_t autonomous_MODE = 0;
volatile uint32_t num_timeout_ROScmd = 0;

// Command mailbox: Teleop owns raw targets; MotorControl owns DesiredSpeed.
// Protect the pair because a double is not an atomic transfer on this MCU.
static volatile double motor_target1 = 0.0, motor_target2 = 0.0;
static void publish_motor_targets(double right, double left)
{
    taskENTER_CRITICAL();
    motor_target1 = right;
    motor_target2 = left;
    taskEXIT_CRITICAL();
}

// RAM-only trace, no ROS/UART traffic. Freeze with dbg_motor_trace_freeze=1.
// sequence is committed last; write_count identifies the next ring slot.
typedef struct {
    uint32_t sequence, ms, dt_ms, encoder_dt_ms, cmd_count, cmd_age_ms;
    uint32_t gap_ms, gap_max_ms, gap_over_500ms, timeouts;
    float cmd_v, cmd_w, raw1, raw2, desired1, desired2, measured1, measured2;
    float pwm1, pwm2;
    uint32_t pid_updated, autonomous;
} MotorTrace;
volatile MotorTrace dbg_motor_trace[128];
volatile uint32_t dbg_motor_trace_write_count = 0;
volatile uint32_t dbg_motor_trace_freeze = 0;
volatile uint32_t dbg_motor_dt_ms = 0, dbg_motor_dt_max_ms = 0;
volatile uint32_t dbg_encoder_dt_ms = 0, dbg_encoder_dt_max_ms = 0;

////Live debug variables - remove if done///////////////////
volatile uint32_t age_ros_check;   //just to check ROS--remove if unnecessary
volatile uint32_t dbg_cmdvel_cb_cnt = 0;
volatile uint32_t dbg_odom_pub_cnt  = 0;
volatile uint32_t dbg_spin_cnt      = 0;

//volatile uint32_t dbg_spin_dt_max_ms = 0;
//volatile uint32_t dbg_spin_dt_last_ms = 0;

//volatile char dbg_rcl_err[120];
volatile uint32_t dbg_rcl_err_cnt = 0;

volatile int dbg_last_odom_rc = 0;
volatile int dbg_odom_init_rc = -999;

//volatile uint32_t dbg_heap_free = 0;
//volatile uint32_t dbg_heap_min = 0;
//volatile uint32_t dbg_stack_hw = 0;
////Live debug variables - remove if done///////////////////

#define CMDVEL_TIMEOUT_MS  500

volatile MP_Mode_t modCtrl = MP_MODE_VELOCITY; //default mode
#define POS_CMD_RESYNC_TH    (0.01f)   // position command step that triggers resync (units of position)
#define SPD_CMD_RESYNC_TH    (0.05f)   // speed command step that triggers resync (units of speed)
static inline float fabsf_fast(double x){ return (x < 0.0f) ? -x : x; }

volatile double SetPos1 = 0.0f;
volatile double SetPos2 = 0.0f;
volatile double SetSpeed1 = 0.0f;
volatile double SetSpeed2 = 0.0f;

//these variables are used to correct the heading
static float g_theta = 0.0f;
static float g_theta_ref = 0.0f;
static float g_e_theta_prev = 0.0f;
static uint8_t g_heading_hold_en = 0;
static uint32_t g_heading_div_ctr = 0;
static float g_heading_omega_corr = 0.0f;
static float g_heading_elapsed_s = 0.0f;
//////////////////////////////////////////////////

volatile int g_activeCell = -1;   // biến dùng cho update lcd

//static volatile uint8_t pid_update_pending = 0;  //biến dùng để update PID từ ROS
static SemaphoreHandle_t pid_mutex;  //kỹ thuật cho phép tạm thời lock trong quá trình thay đổi biến PID, tránh bị cập nhật nửa chừng

volatile uint16_t touch_x = 0;
volatile uint16_t touch_y = 0;
volatile uint8_t  touch_pressed = 0;

//UI variables/definition please put here////////////////////////////////////////////////
typedef struct {
    uint16_t x, y, w, h;
    const char* label;
    uint8_t id;
} UICell_t;

static inline int pointInRect(uint16_t px, uint16_t py, const UICell_t* r)
{
    return (px >= r->x) && (px < r->x + r->w) &&
           (py >= r->y) && (py < r->y + r->h);
}
enum {
    CELL_PWM1 = 0,
    CELL_PWM2,
    CELL_ENC1,
    CELL_ENC2,
    CELL_V1,
    CELL_V2,
    CELL_FIGURE,
    CELL_CONTROLLER,
    CELL_ODOMX,
    CELL_ODOMY,
    CELL_YAW,
    CELL_SETTING_PID,
    CELL_COUNT
};
//UI variables/definition please put here////////////////////////////////////////////////

////Odometry ROS2 sync time////////////////
static bool microros_time_synced = false;

static void microros_sync_time(void)
{
    if (rmw_uros_sync_session(1000) == RMW_RET_OK)
    {
        microros_time_synced = true;
    }
    else
    {
        microros_time_synced = false;
    }
}
/////////////////////////////////////////////////////////

//PS2 control variables -- PUT HERE////////////////////////
typedef struct {
  uint32_t tick;
  uint8_t  id;
  uint16_t buttons;
  uint8_t  lx, ly, rx, ry;
  uint8_t  ok;
  uint8_t  analog;
} PS2X_State;

static PS2X_Handle ps2;

// Shared snapshot for other tasks
static PS2X_State g_ps2_state;
static osMutexId_t g_ps2_mutex;

static inline float clampf(float x, float lo, float hi) {
    if (x < lo) return lo;
    if (x > hi) return hi;
    return x;
}

static inline float apply_deadband_and_min(float cmd, float deadband, float min_eff)
{
  float a = fabsf(cmd);
  if (a < deadband) return 0.0f;                     // true zero
  if (a < min_eff)  return copysignf(min_eff, cmd);  // stiction boost
  return cmd;
}

static float wrap_pi(float a)
{
    while (a > 3.1415926f)  a -= 2.0f * 3.1415926f;
    while (a < -3.1415926f) a += 2.0f * 3.1415926f;
    return a;
}

static inline int is_pressed(uint16_t buttons, uint16_t mask) {
    return (buttons & mask) ? 1 : 0;
}
//PS2 control variables -- PUT HERE////////////////////////

//////////This variables and functions are used to kick start the robot in case the cmd is too small////////
static uint32_t stuck_ms = 0;

static inline uint32_t ms_now(void) { return (uint32_t)(xTaskGetTickCount() * portTICK_PERIOD_MS); }

void apply_stiction_kick(float *vL_cmd, float *vR_cmd, float vL_meas, float vR_meas, uint32_t dt_ms)
{
    const float CMD_EPS   = 0.02f;   // command considered "wants to move"
    const float MEAS_EPS  = 0.01f;   // measured considered "still not moving"
    const uint32_t STUCK_TIME_MS = 200;

    const float KICK_ADD  = 0.03f;   // m/s extra push
    const float KICK_MAX  = 0.20f;   // m/s cap for kick effect

    float v_avg_cmd  = 0.5f * (*vL_cmd + *vR_cmd);
    float v_avg_meas = 0.5f * (vL_meas + vR_meas);

    if (fabsf(v_avg_cmd) > CMD_EPS && fabsf(v_avg_meas) < MEAS_EPS) {
        if (stuck_ms < STUCK_TIME_MS) {
            stuck_ms += dt_ms;
        }
        if (stuck_ms >= STUCK_TIME_MS) {
            float add = copysignf(KICK_ADD, v_avg_cmd);
            add = clampf(add, -KICK_MAX, KICK_MAX);
            *vL_cmd += add;
            *vR_cmd += add;
        }
    } else {
        stuck_ms = 0;
    }
}
///////////////////////////////////////////////////////////////////////////

//bien dung de cap nhat du lieu len locLCD
typedef struct {
  int32_t enc1, enc2;
  float   v1, v2;
  float   v1d, v2d;
} EncData_t;

typedef struct {
  float x, y, yaw;
} OdomData_t;

typedef struct {
  float pwm1, pwm2;
} MotorData_t;

// dữ liệu hiện tại
static EncData_t   g_encData;
static OdomData_t  g_odomData;
static MotorData_t g_motorData;

// sequence numbers (odd = đang ghi, even = xong)
static volatile uint32_t g_encSeq   = 0;
static volatile uint32_t g_odomSeq  = 0;
static volatile uint32_t g_motorSeq = 0;

// memory barrier (CMSIS)
#ifndef __DMB
#define __DMB() __asm volatile ("dmb 0xF":::"memory")
#endif

/* USER CODE END Includes */

/* USER CODE BEGIN PTD */
static inline void EncData_Publish(int32_t enc1, int32_t enc2, float v1, float v2, float v1d, float v2d);
static inline void OdomData_Publish(float x, float y, float yaw);
static inline void MotorData_Publish(float pwm1, float pwm2);

static bool microros_odom_init(rcl_node_t * node);
static void microros_odom_fini(rcl_node_t *node);
static void microros_publish_odom(void);
static void cmdvel_cb(const void * msgin);
static void pid_cb(const void * msgin);

bool cubemx_transport_open(struct uxrCustomTransport * transport);
bool cubemx_transport_close(struct uxrCustomTransport * transport);
size_t cubemx_transport_write(struct uxrCustomTransport* transport, const uint8_t * buf, size_t len, uint8_t * err);
size_t cubemx_transport_read(struct uxrCustomTransport* transport, uint8_t* buf, size_t len, int timeout, uint8_t* err);

void * microros_allocate(size_t size, void * state);
void microros_deallocate(void * pointer, void * state);
void * microros_reallocate(void * pointer, size_t size, void * state);
void * microros_zero_allocate(size_t number_of_elements, size_t size_of_element, void * state);

#define RCCHECK(fn)  do { rcl_ret_t rc = (fn); if (rc != RCL_RET_OK) return false; } while(0)
#define RCSOFTCHECK(fn) do { (void)(fn); } while(0)

//this is used to let it waits for connect
//static void wait_for_agent_forever(void)
//{
//  while (rmw_uros_ping_agent(200, 1) != RMW_RET_OK)
//  {
//    osDelay(200);
//  }
//}

extern struct netif gnetif;

static bool network_is_ready(void)
{
  if (!netif_is_link_up(&gnetif)) return false;
  if (ip4_addr_isany_val(*netif_ip4_addr(&gnetif))) return false;
  return true;
}

static bool create_entities(
    rclc_support_t *support,
    rcl_node_t *node,
    rcl_subscription_t *sub_cmdvel,
    rclc_executor_t *executor,
    rcl_allocator_t *allocator,
    geometry_msgs__msg__Twist *msg_cmdvel)
{
    rcl_ret_t rc;

    // =====================================================
    // 1. Support / XRCE session
    // =====================================================
    rc = rclc_support_init(
        support,
        0,
        NULL,
        allocator
    );

    if (rc != RCL_RET_OK)
    {
        rcl_reset_error();
        return false;
    }

    g_support_initialized = true;

    // =====================================================
    // 2. Node
    // =====================================================
    rc = rclc_node_init_default(
        node,
        "stm32_odom_node",
        "",
        support
    );

    if (rc != RCL_RET_OK)
    {
        rcl_reset_error();
        return false;
    }

    g_node_initialized = true;

    // =====================================================
    // 3. Odom publisher
    // =====================================================
    if (!microros_odom_init(node))
    {
        rcl_reset_error();
        return false;
    }

    // =====================================================
    // 4. cmd_vel subscription
    // =====================================================
    rmw_qos_profile_t qos_cmdvel =
        rmw_qos_profile_default;

    qos_cmdvel.reliability =
        RMW_QOS_POLICY_RELIABILITY_BEST_EFFORT;

    qos_cmdvel.durability =
        RMW_QOS_POLICY_DURABILITY_VOLATILE;

    qos_cmdvel.history =
        RMW_QOS_POLICY_HISTORY_KEEP_LAST;

    qos_cmdvel.depth = 1;

    rc = rclc_subscription_init(
        sub_cmdvel,
        node,
        ROSIDL_GET_MSG_TYPE_SUPPORT(
            geometry_msgs,
            msg,
            Twist
        ),
        "cmd_vel",
        &qos_cmdvel
    );

    if (rc != RCL_RET_OK)
    {
        rcl_reset_error();
        return false;
    }

    g_sub_cmdvel_initialized = true;

    // =====================================================
    // 5. Executor
    // =====================================================
    rc = rclc_executor_init(
        executor,
        &support->context,
        1,
        allocator
    );

    if (rc != RCL_RET_OK)
    {
        rcl_reset_error();
        return false;
    }

    g_executor_initialized = true;

    // =====================================================
    // 6. Add subscription vào executor
    // =====================================================
    rc = rclc_executor_add_subscription(
        executor,
        sub_cmdvel,
        msg_cmdvel,
        &cmdvel_cb,
        ON_NEW_DATA
    );

    if (rc != RCL_RET_OK)
    {
        rcl_reset_error();
        return false;
    }

    return true;
}

static void destroy_entities(
    rclc_executor_t *executor,
    rcl_subscription_t *sub_cmdvel,
    rcl_node_t *node,
    rclc_support_t *support)
{
    // =====================================================
    // Agent có thể đã chết.
    // Không chờ ACK khi destroy XRCE entities/session.
    // =====================================================
    if (g_support_initialized)
    {
        rmw_context_t *rmw_context =
            rcl_context_get_rmw_context(
                &support->context
            );

        if (rmw_context != NULL)
        {
            (void)
            rmw_uros_set_context_entity_destroy_session_timeout(
                rmw_context,
                0
            );
        }
    }

    // =====================================================
    // Executor
    // =====================================================
    if (g_executor_initialized)
    {
        (void)rclc_executor_fini(
            executor
        );

        g_executor_initialized = false;
    }

    // =====================================================
    // cmd_vel subscription
    // =====================================================
    if (g_sub_cmdvel_initialized &&
        g_node_initialized)
    {
        (void)rcl_subscription_fini(
            sub_cmdvel,
            node
        );

        g_sub_cmdvel_initialized = false;
    }

    // =====================================================
    // odom publisher + odom message
    // =====================================================
    if (g_node_initialized)
    {
        microros_odom_fini(node);
    }

    // =====================================================
    // Node
    // =====================================================
    if (g_node_initialized)
    {
        (void)rcl_node_fini(
            node
        );

        g_node_initialized = false;
    }

    // =====================================================
    // Support / context / session
    // =====================================================
    if (g_support_initialized)
    {
        (void)rclc_support_fini(
            support
        );

        g_support_initialized = false;
    }

    // =====================================================
    // Quan trọng:
    // đưa toàn bộ handles về zero-state trước lần create mới.
    // =====================================================
    *support =
        (rclc_support_t){0};

    *node =
        (rcl_node_t){0};

    *sub_cmdvel =
        (rcl_subscription_t){0};

    *executor =
        (rclc_executor_t){0};

    g_msg_cmdvel =
        (geometry_msgs__msg__Twist){0};

    odom_pub_fail_streak = 0;

    rcl_reset_error();
}
/* USER CODE END PTD */

/* Definitions for defaultTask */
osThreadId_t defaultTaskHandle;
const osThreadAttr_t defaultTask_attributes = {
  .name = "defaultTask",
  .stack_size = 3000 * 4,
  .priority = (osPriority_t) osPriorityNormal,
};

/* USER CODE BEGIN FunctionPrototypes */
osThreadId_t encoderTaskHandle;
osThreadId_t motorTaskHandle;
osThreadId_t odometryTaskHandle;
osThreadId_t touchTaskHandle;
osThreadId_t PS2TaskHandle;
//osThreadId_t LCDTaskHandle;
osThreadId_t teleopTaskHandle;
//osThreadId_t motionTaskHandle;

const osThreadAttr_t encoderTask_attributes = {
  .name       = "EncoderTask",
  .priority   = (osPriority_t) osPriorityRealtime,
  .stack_size = 256 * 4
};
const osThreadAttr_t motorTask_attributes = {
  .name       = "MotorTask",
  .priority   = (osPriority_t) osPriorityRealtime,
  .stack_size = 256 * 4
};
const osThreadAttr_t odometryTask_attributes = {
  .name       = "OdometryTask",
  .priority   = (osPriority_t) osPriorityRealtime,
  .stack_size = 256 * 4
};
static const osThreadAttr_t touchTask_attributes = {
      .name = "TouchTask",
      .stack_size = 512 * 4,              // bytes
      .priority = (osPriority_t) osPriorityBelowNormal
};
const osThreadAttr_t PS2Task_attributes = {
  .name       = "PS2Task",
  .stack_size = 512 * 4,   // 2KB stack (đủ cho parse HID)
  .priority   = (osPriority_t) osPriorityNormal
};
const osThreadAttr_t teleopTask_attributes = {
  .name = "TeleopTask",
  .priority = (osPriority_t) osPriorityNormal,
  .stack_size = 512 * 4   // bytes (512 words if you think in words; here it's bytes)
};
//const osThreadAttr_t lcdTask_attributes = {
//  .name = "lcdTask",
//  .stack_size = 1024,
//  .priority = (osPriority_t) osPriorityLow  // UI để Low là hợp lý
//};
//const osThreadAttr_t motionTask_attributes = {
//  .name = "motionTask",
//  .stack_size = 512 * 4,
//  .priority = (osPriority_t) osPriorityNormal  // UI để Low là hợp lý
//};

void StartUITask(void *argument);
void EncoderTask(void *argument);
void MotorControlTask(void *argument);
void OdometryTask(void *argument);
//void MotionTask(void *argument);
void TouchTask(void *argument);
void StartPS2Task(void *argument);
void StartLCDTask(void *argument);
void StartTeleopTask(void *argument);
void StartMicroRosSpinTask(void *argument);
void StartOdomPubTask(void *argument);

void StartMicroRosRxTask(void *argument);
void StartMicroRosOdomPubTask(void *argument);
/* USER CODE END FunctionPrototypes */

void StartDefaultTask(void *argument);

extern void MX_LWIP_Init(void);
void MX_FREERTOS_Init(void); /* (MISRA C 2004 rule 8.1) */

void MX_FREERTOS_Init(void) {
  /* USER CODE BEGIN Init */
  pid_mutex = xSemaphoreCreateMutex();
  g_ps2_mutex = osMutexNew(NULL);

  encoderTaskHandle = osThreadNew(EncoderTask, NULL, &encoderTask_attributes);
  motorTaskHandle   = osThreadNew(MotorControlTask, NULL, &motorTask_attributes);
  odometryTaskHandle = osThreadNew(OdometryTask, NULL, &odometryTask_attributes);
  touchTaskHandle = osThreadNew(TouchTask_Start, NULL, &touchTask_attributes);
  PS2TaskHandle = osThreadNew(StartPS2Task, NULL, &PS2Task_attributes);
  teleopTaskHandle = osThreadNew(StartTeleopTask, NULL, &teleopTask_attributes);
  //LCDTaskHandle = osThreadNew(StartLCDTask, NULL, &lcdTask_attributes);
//  motionTaskHandle = osThreadNew(MotionTask, NULL, &motionTask_attributes);
  /* USER CODE END Init */

  /* Create the thread(s) */
  /* creation of defaultTask */
  defaultTaskHandle = osThreadNew(StartDefaultTask, NULL, &defaultTask_attributes);

}

/* USER CODE BEGIN Application */
// Định nghĩa các trạng thái cho State Machine
typedef enum {
    UROS_STATE_WAIT_NET = 0,
    UROS_STATE_WAIT_AGENT,
    UROS_STATE_CREATE_ENTITIES,
    UROS_STATE_RUN,
    UROS_STATE_DESTROY
} uros_state_t;

void StartDefaultTask(void *argument)
{
    (void)argument;

    HAL_GPIO_WritePin(GPIOB, GPIO_PIN_0, GPIO_PIN_SET);

    // 1) Bring up LwIP
    MX_LWIP_Init();
    osDelay(300);

    // 2) micro-ROS custom UDP transport
    static const char *agent_ip = "192.168.4.150";

    rmw_uros_set_custom_transport(
        false,
        (void *)agent_ip,
        cubemx_transport_open,
        cubemx_transport_close,
        cubemx_transport_write,
        cubemx_transport_read
    );

    // 3) FreeRTOS allocator
    rcl_allocator_t freeRTOS_allocator = rcutils_get_zero_initialized_allocator();
    freeRTOS_allocator.allocate      = microros_allocate;
    freeRTOS_allocator.deallocate    = microros_deallocate;
    freeRTOS_allocator.reallocate    = microros_reallocate;
    freeRTOS_allocator.zero_allocate = microros_zero_allocate;

    rcutils_set_default_allocator(&freeRTOS_allocator);
    g_allocator = rcl_get_default_allocator();

    // Create mutex 1 lần
    if (g_uros_mutex == NULL) {
        g_uros_mutex = osMutexNew(NULL);
    }

    // Create RX task 1 lần
    if (g_rx_task_handle == NULL) {
        const osThreadAttr_t rxTask_attributes = {
            .name = "uROS_RX",
            .stack_size = 1024 * 4,
            .priority = (osPriority_t) osPriorityAboveNormal
        };
        g_rx_task_handle = osThreadNew(StartMicroRosRxTask, NULL, &rxTask_attributes);
    }

    // Create Odom task 1 lần
    if (g_odom_task_handle == NULL) {
        const osThreadAttr_t odomTask_attributes = {
            .name = "uROS_ODOM",
            .stack_size = 1024 * 4,
            .priority = (osPriority_t) osPriorityNormal
        };
        g_odom_task_handle = osThreadNew(StartMicroRosOdomPubTask, NULL, &odomTask_attributes);
    }

    // State Machine Variables
    uros_state_t state = UROS_STATE_WAIT_NET;

    uint8_t run_ping_fail_cnt = 0;
    uint8_t wait_agent_fail_cnt = 0;

    uint32_t last_watchdog_ms = 0;
    uint32_t last_eth_recovery_ms = 0;

    for (;;)
    {
        // Liên tục cập nhật dữ liệu touch (theo code cũ của bạn)
        touch_x = g_touchState.x;
        touch_y = g_touchState.y;
        touch_pressed = g_touchState.pressed;

        switch (state)
        {
            case UROS_STATE_WAIT_NET:
                if (network_is_ready()) {
                    state = UROS_STATE_WAIT_AGENT;
                } else {
                    osDelay(200);
                }
                break;

            case UROS_STATE_WAIT_AGENT:
            {
                if (!network_is_ready())
                {
                    wait_agent_fail_cnt = 0;
                    state = UROS_STATE_WAIT_NET;
                    break;
                }

                if (rmw_uros_ping_agent(100, 2) == RMW_RET_OK)
                {
                    // Network RX/TX + Agent đều hoạt động
                    wait_agent_fail_cnt = 0;

                    state = UROS_STATE_CREATE_ENTITIES;
                    break;
                }

                /*
                * PHY vẫn UP nhưng không nói chuyện được với Agent.
                *
                * Không recovery ngay vì lúc mini-PC mới boot
                * Agent có thể chưa chạy.
                */
                if (wait_agent_fail_cnt < 255U)
                {
                    wait_agent_fail_cnt++;
                }

                /*
                * 20 lần x 500 ms ~= 10 giây.
                *
                * Nếu sau khoảng 10 giây vẫn không nhận được
                * phản hồi thì có khả năng ETH RX/MAC/DMA bị kẹt.
                */
                if (wait_agent_fail_cnt >= 20U)
                {
                    uint32_t now = osKernelGetTickCount();

                    /*
                    * Giới hạn tần suất recovery để tránh
                    * reset Ethernet liên tục khi mini-PC thật sự tắt.
                    */
                    if ((now - last_eth_recovery_ms) >= 10000U)
                    {
                        last_eth_recovery_ms = now;

                        dbg_eth_recovery_cnt++;
                        ethernet_request_recovery();
                    }

                    wait_agent_fail_cnt = 0;

                    /*
                    * Cho ethernet_link_thread đủ thời gian:
                    *
                    * HAL_ETH_Stop_IT
                    * HAL_ETH_DeInit
                    * HAL_ETH_Init
                    * HAL_ETH_Start_IT
                    */
                    osDelay(1500);

                    state = UROS_STATE_WAIT_NET;
                    break;
                }

                osDelay(500);
                break;
            }

            case UROS_STATE_CREATE_ENTITIES:
                if (osMutexAcquire(g_uros_mutex, 100) == osOK) {
                    bool ok = create_entities(&g_support, &g_node, &g_sub_cmdvel, &g_executor, &g_allocator, &g_msg_cmdvel);

                    if (!ok) {
                        destroy_entities(&g_executor, &g_sub_cmdvel, &g_node, &g_support);
                        osMutexRelease(g_uros_mutex);
                        state = UROS_STATE_WAIT_AGENT;
                        osDelay(200);
                        break;
                    }

                    // Đồng bộ thời gian
                    (void)rmw_uros_sync_session(500);
                    osMutexRelease(g_uros_mutex);

                    // Thiết lập cờ cho các Task chạy
                    g_request_reconnect = false;
                    g_uros_connected = true;

                    run_ping_fail_cnt = 0;
                    last_watchdog_ms = osKernelGetTickCount();
                    state = UROS_STATE_RUN;
                }
                break;

            case UROS_STATE_RUN:
                // Nếu Task Odom hoặc Task Rx phát hiện lỗi -> yêu cầu reconnect
                if (g_request_reconnect) {
                    state = UROS_STATE_DESTROY;
                    break;
                }

                uint32_t now_ms = osKernelGetTickCount();
                // Watchdog: Ping nhẹ mỗi 3 giây để kiểm tra agent có đột ngột biến mất không
                if ((now_ms - last_watchdog_ms) >= 3000U) {
                    last_watchdog_ms = now_ms;
                    bool ping_ok = false;

                    if (network_is_ready()) {
                        if (osMutexAcquire(g_uros_mutex, 50) == osOK) {
                            ping_ok = (rmw_uros_ping_agent(20, 1) == RMW_RET_OK);
                            osMutexRelease(g_uros_mutex);
                        }
                    }

                    if (!ping_ok) {
                        run_ping_fail_cnt++;
                    } else {
                        run_ping_fail_cnt = 0;
                    }

                    // Nếu mất kết nối 3 lần liên tiếp, chuyển sang bước hủy kết nối
                    if (run_ping_fail_cnt >= 3U) {
                        dbg_manager_reconnect_cnt++;
                        g_request_reconnect = true;
                        state = UROS_STATE_DESTROY;
                    }
                }
                osDelay(50);
                break;

            case UROS_STATE_DESTROY:
                // Ngắt cờ để các Task Rx và Odom ngừng chọc vào g_executor ngay lập tức
                g_uros_connected = false;
                g_request_reconnect = true;

                osDelay(50); // Cho Rx/Odom task thời gian nhả Mutex ra

                // Chờ lấy được Mutex thì mới hủy thực thể
                if (osMutexAcquire(g_uros_mutex, osWaitForever) == osOK) {
                    destroy_entities(&g_executor, &g_sub_cmdvel, &g_node, &g_support);
                    osMutexRelease(g_uros_mutex);
                }

                g_request_reconnect = false;
                state = UROS_STATE_WAIT_AGENT;
                osDelay(100);
                break;
        }
    }
}

//////////////////THIS PART IS MICROROS USING UDP TRANSPORT-testing with statemachine///////////////
//////////////////////////////////////////////////////////////////////////
//void StartDefaultTask(void *argument)
//{
//  (void)argument;
//
//  HAL_GPIO_WritePin(GPIOB, GPIO_PIN_0, GPIO_PIN_SET);
//
//  // 1) Bring up LwIP
//  MX_LWIP_Init();
//  osDelay(300);
//
//  // 2) micro-ROS custom UDP transport
//  static const char * agent_ip = "192.168.4.150";
//
//  rmw_uros_set_custom_transport(
//    false,
//    (void*)agent_ip,
//    cubemx_transport_open,
//    cubemx_transport_close,
//    cubemx_transport_write,
//    cubemx_transport_read
//  );
//
//  // 3) FreeRTOS allocator
//  rcl_allocator_t freeRTOS_allocator = rcutils_get_zero_initialized_allocator();
//  freeRTOS_allocator.allocate      = microros_allocate;
//  freeRTOS_allocator.deallocate    = microros_deallocate;
//  freeRTOS_allocator.reallocate    = microros_reallocate;
//  freeRTOS_allocator.zero_allocate = microros_zero_allocate;
//  rcutils_set_default_allocator(&freeRTOS_allocator);
//
//  rcl_allocator_t allocator = rcl_get_default_allocator();
//
//  // micro-ROS objects
//  rclc_support_t support = {0};
//  rcl_node_t node = {0};
//  rcl_subscription_t sub_cmdvel = {0};
//  rclc_executor_t executor = {0};
//  geometry_msgs__msg__Twist msg_cmdvel;
//
//  // State machine
//  microros_state_t state = MICROROS_WAIT_NET;
//
//  // Fast loop config
//  const uint64_t spin_timeout_ns = 2ULL * 1000000ULL;   // 2 ms
//  const TickType_t period = pdMS_TO_TICKS(10);          // 100 Hz loop
//
//  // Timing
//  TickType_t last_wake_time = xTaskGetTickCount();
//  uint32_t last_odom_ms = 0;
//  uint32_t last_watchdog_ms = 0;
//
//  // Watchdog / reconnect
//  uint8_t runtime_ping_fail_cnt = 0;
//
//  // Optional debug
//  // uint32_t last_debug_ms = 0;
//
//  for (;;)
//  {
//    switch (state)
//    {
//      case MICROROS_WAIT_NET:
//      {
//        if (network_is_ready())
//        {
//          state = MICROROS_WAIT_AGENT;
//        }
//        else
//        {
//          osDelay(200);
//        }
//        break;
//      }
//
//      case MICROROS_WAIT_AGENT:
//      {
//        // Chỉ ping ở state này, không ping trong fast loop
//        if (rmw_uros_ping_agent(50, 1) == RMW_RET_OK)
//        {
//          state = MICROROS_CREATE_SESSION;
//        }
//        else
//        {
//          osDelay(500);
//        }
//        break;
//      }
//
//      case MICROROS_CREATE_SESSION:
//      {
//        bool ok = create_entities(
//          &support,
//          &node,
//          &sub_cmdvel,
//          &executor,
//          &allocator,
//          &msg_cmdvel
//        );
//
//        if (!ok)
//        {
//          destroy_entities(&executor, &sub_cmdvel, &node, &support);
//          osDelay(200);
//          state = MICROROS_WAIT_AGENT;
//          break;
//        }
//
//        // Sync ROS time 1 lần sau khi connect / reconnect thành công
//        // Không cần ép buộc phải thành công mới RUN, nhưng nên thử
//        (void)rmw_uros_sync_session(500);
//
//        // Reset runtime timing
//        last_wake_time = xTaskGetTickCount();
//        last_odom_ms = osKernelGetTickCount();
//        last_watchdog_ms = osKernelGetTickCount();
//        runtime_ping_fail_cnt = 0;
//
//        state = MICROROS_RUN;
//        break;
//      }
//
//      case MICROROS_RUN:
//      {
//        // 1) đọc dữ liệu ROS2 / gọi callback như cmdvel_cb()
//        rcl_ret_t rc = rclc_executor_spin_some(&executor, spin_timeout_ns);
//
//        // Nếu executor lỗi thật thì reconnect
//        if (rc != RCL_RET_OK && rc != RCL_RET_TIMEOUT)
//        {
//          state = MICROROS_RECONNECT;
//          break;
//        }
//
//        // 2) phần xử lý local khác của bạn
//        touch_x = g_touchState.x;
//        touch_y = g_touchState.y;
//        touch_pressed = g_touchState.pressed;
//
//        uint32_t now_ms = osKernelGetTickCount();
//
//        microros_publish_odom(); //publish odom
//
//        // 4) watchdog nhẹ, rất thưa, để phát hiện agent reset
//        // Không check quá nhanh để tránh ảnh hưởng loop
//        if ((now_ms - last_watchdog_ms) >= 5000U)   // mỗi 5 giây
//        {
//          last_watchdog_ms = now_ms;
//
//          if (!network_is_ready() || rmw_uros_ping_agent(20, 1) != RMW_RET_OK)
//          {
//            runtime_ping_fail_cnt++;
//          }
//          else
//          {
//            runtime_ping_fail_cnt = 0;
//          }
//
//          // Fail liên tiếp thì coi như mất session -> reconnect
//          if (runtime_ping_fail_cnt >= 3U)
//          {
//            state = MICROROS_RECONNECT;
//            break;
//          }
//        }
//
//        // Optional debug mỗi 1 giây
//        /*
//        if ((now_ms - last_debug_ms) >= 1000U)
//        {
//          last_debug_ms = now_ms;
//          printf("[uROS] RUN ok, heap=%lu, min_heap=%lu\r\n",
//                 (unsigned long)xPortGetFreeHeapSize(),
//                 (unsigned long)xPortGetMinimumEverFreeHeapSize());
//        }
//        */
//
//        // 5) giữ loop 100 Hz
//        vTaskDelayUntil(&last_wake_time, period);
//        break;
//      }
//
//      case MICROROS_RECONNECT:
//      {
//        destroy_entities(&executor, &sub_cmdvel, &node, &support);
//
//        // Reset object handles về zero-state cho an toàn
//        support = (rclc_support_t){0};
//        node = (rcl_node_t){0};
//        sub_cmdvel = (rcl_subscription_t){0};
//        executor = (rclc_executor_t){0};
//
//        osDelay(200);
//        state = MICROROS_WAIT_AGENT;
//        break;
//      }
//
//      default:
//      {
//        state = MICROROS_WAIT_NET;
//        break;
//      }
//    }
//  }
//}

//void StartDefaultTask(void *argument)
//{
//    (void)argument;
//    HAL_GPIO_WritePin(GPIOB, GPIO_PIN_0, GPIO_PIN_SET);
//
//    MX_LWIP_Init();
//    osDelay(300);
//
//    static const char * agent_ip = "192.168.4.150";
//
//    rmw_uros_set_custom_transport(
//        false,
//        (void*)agent_ip,
//        cubemx_transport_open,
//        cubemx_transport_close,
//        cubemx_transport_write,
//        cubemx_transport_read
//    );
//
//    // allocator như bạn đang làm
//    rcl_allocator_t freeRTOS_allocator = rcutils_get_zero_initialized_allocator();
//    freeRTOS_allocator.allocate      = microros_allocate;
//    freeRTOS_allocator.deallocate    = microros_deallocate;
//    freeRTOS_allocator.reallocate    = microros_reallocate;
//    freeRTOS_allocator.zero_allocate = microros_zero_allocate;
//    rcutils_set_default_allocator(&freeRTOS_allocator);
//
//    microros_mutex_init();
//
//    // tạo 2 task
//    osThreadNew(StartMicroRosSpinTask, NULL, &urosSpin_attr);
//    osThreadNew(StartOdomPubTask, NULL, &urosOdom_attr);
//
//    // DefaultTask không cần làm gì nữa
//    vTaskDelete(NULL);
//}
//////////////////THIS PART IS MICROROS USING UDP TRANSPORT///////////////
//////////////////////////////////////////////////////////////////////////

/////////////////THIS PART IS MICROROS USING UART//////////////////////////////////////
//////////////////////////////////////////////////////////////////////////////////////
//void StartDefaultTask(void *argument)
//{
//  HAL_GPIO_WritePin(GPIOB, GPIO_PIN_0, GPIO_PIN_SET);
//
//  rmw_uros_set_custom_transport(
//    true,
//    (void *) &huart3,
//    cubemx_transport_open,
//    cubemx_transport_close,
//    cubemx_transport_write,
//    cubemx_transport_read);
//
//  // Allocator FreeRTOS (your code)
//  rcl_allocator_t freeRTOS_allocator = rcutils_get_zero_initialized_allocator();
//  freeRTOS_allocator.allocate      = microros_allocate;
//  freeRTOS_allocator.deallocate    = microros_deallocate;
//  freeRTOS_allocator.reallocate    = microros_reallocate;
//  freeRTOS_allocator.zero_allocate = microros_zero_allocate;
//  rcutils_set_default_allocator(&freeRTOS_allocator);
//
//  rcl_allocator_t allocator = rcl_get_default_allocator();
//
//  // micro-ROS objects (keep them outside so we can destroy/recreate)
//  rclc_support_t support;
//  rcl_node_t node;
//  rcl_subscription_t sub_cmdvel;
//  rcl_subscription_t sub_pid;
//  rclc_executor_t executor;
//
//  geometry_msgs__msg__Twist msg_cmdvel;
//  std_msgs__msg__Float64MultiArray msg_pid;
//
//  const uint32_t period_ms = 10;
//  const float dt = 0.010f;
//  const uint64_t spin_timeout_ns = 2ULL * 1000000ULL;
//
//  for (;;)
//  {
//    // 1) Wait for agent (no reset needed)
//    osDelay(300);
//    wait_for_agent_forever();
//
//    // 2) Create entities; if fails, retry
//    bool ok = create_entities(&support, &node, &sub_cmdvel, &sub_pid, &executor,
//                              &allocator, &msg_cmdvel, &msg_pid);
//
//    if (!ok)
//    {
//      destroy_entities(&executor, &sub_cmdvel, &sub_pid, &node, &support);
//      osDelay(500);
//      continue;
//    }
//
//    // 3) Normal running loop (until agent disappears)
////    float last_x = odom_x, last_y = odom_y, last_theta = odom_theta;
//
//    while (rmw_uros_ping_agent(100, 1) == RMW_RET_OK)
//    {
//      touch_x = g_touchState.x;
//      touch_y = g_touchState.y;
//      touch_pressed = g_touchState.pressed;
//
////      float curr_x = odom_x, curr_y = odom_y, curr_theta = odom_theta;
////
////      odom_vx  = (curr_x - last_x) / dt;
////      odom_vy  = (curr_y - last_y) / dt;
////      odom_vth = (curr_theta - last_theta) / dt;
////
////      last_x = curr_x; last_y = curr_y; last_theta = curr_theta;
//
//      microros_publish_odom();
//      rclc_executor_spin_some(&executor, spin_timeout_ns);
//
//      osDelay(period_ms);
//    }
//
//    // 4) Agent lost → cleanup and go back to waiting
//    destroy_entities(&executor, &sub_cmdvel, &sub_pid, &node, &support);
//    osDelay(500);
//  }
//}
/////////////////THIS PART IS MICROROS USING UART//////////////////////////////////////
//////////////////////////////////////////////////////////////////////////////////////

void EncoderTask(void *argument)
{
	const TickType_t period = pdMS_TO_TICKS(ENCODER_PERIOD_MS);
	TickType_t lastWake = xTaskGetTickCount();
    TickType_t lastSample = lastWake;

  for(;;)
  {
    TickType_t sample = xTaskGetTickCount();
    TickType_t elapsed = sample - lastSample;
    if (elapsed == 0) {
        vTaskDelayUntil(&lastWake, period);
        continue;
    }
    lastSample = sample;
    float encoder_dt = (float)elapsed / configTICK_RATE_HZ;
    dbg_encoder_dt_ms = elapsed * portTICK_PERIOD_MS;
    if (dbg_encoder_dt_ms > dbg_encoder_dt_max_ms)
        dbg_encoder_dt_max_ms = dbg_encoder_dt_ms;
    // Đọc count mở rộng
	g_encCount1 = Encoder_GetCount(ENCODER_1);
    g_encCount2 = Encoder_GetCount(ENCODER_2);

    g_speed1_mps = Encoder_GetSpeed_mps(ENCODER_1,encoder_dt);
    g_speed2_mps = Encoder_GetSpeed_mps(ENCODER_2,encoder_dt);

    CurSpeed1 = g_speed1_mps;
    CurSpeed2 = g_speed2_mps;

    float vL_meas = CurSpeed2;
    float vR_meas = CurSpeed1;

    float theta_dot = (vR_meas - vL_meas) / WHEEL_BASE_M;
    g_theta = wrap_pi(g_theta + theta_dot * encoder_dt);

    EncData_Publish(g_encCount1, g_encCount2, g_speed1_mps, g_speed2_mps, DesiredSpeed1, DesiredSpeed2);

    vTaskDelayUntil(&lastWake, period);
  }
}

void MotorControlTask(void *argument)
{
	const TickType_t period = pdMS_TO_TICKS(MOTORCONTROL_PERIOD_MS);
	TickType_t lastWake = xTaskGetTickCount();

	TickType_t lastStep = lastWake;
	static double smoothed_speed1 = 0.0;
	static double smoothed_speed2 = 0.0;

	for (;;)
	    {
			TickType_t step = xTaskGetTickCount();
            TickType_t elapsed = step - lastStep;
            lastStep = step;
            dbg_motor_dt_ms = elapsed * portTICK_PERIOD_MS;
            if (dbg_motor_dt_ms > dbg_motor_dt_max_ms)
                dbg_motor_dt_max_ms = dbg_motor_dt_ms;
            // Never compensate a missed deadline with a large command jump.
            float ramp_dt = (float)(elapsed > period ? period : elapsed) / configTICK_RATE_HZ;
            //update thông số PID nếu có thay đổi
			if (pid_update_pending)
			{
				if (pid_mutex) xSemaphoreTake(pid_mutex, pdMS_TO_TICKS(2));

				PID_SetTunings(&SpeedPID1, Kp1, Ki1, Kd1);
				PID_SetTunings(&SpeedPID2, Kp2, Ki2, Kd2);
				PID_SetTunings(&PosPID1, Kp1, Ki1, Kd1);
				PID_SetTunings(&PosPID2, Kp2, Ki2, Kd2);

				pid_update_pending = 0;

				if (pid_mutex) xSemaphoreGive(pid_mutex);
			}

			if (modCtrl == MP_MODE_POSITION) {
				PID_Compute(&PosPID1);
				PID_Compute(&PosPID2);
				MotorData_Publish(PosPIDOut1, PosPIDOut2);  //update PWM data for LCD display
				Motor_SetSpeed(MOTOR_1,PosPIDOut1);
				Motor_SetSpeed(MOTOR_2,PosPIDOut2);
			} else {
				//Decide whether to enable heading hold (straight mode detection with latch)
				taskENTER_CRITICAL();
                float raw1 = motor_target1;
                float raw2 = motor_target2;
                taskEXIT_CRITICAL();
                float vL_ref_cmd = raw2;
                float vR_ref_cmd = raw1;

				float v_avg_cmd = 0.5f * (vL_ref_cmd + vR_ref_cmd);
				float dv_cmd    = (vR_ref_cmd - vL_ref_cmd);

				uint8_t want_heading_hold =
				    (fabsf(dv_cmd) < EPS_TURN_MPS) &&
				    (fabsf(v_avg_cmd) > EPS_MOVE_MPS);

				//Then detect rising edge to latch heading reference:
				if (want_heading_hold && !g_heading_hold_en) {
				    g_theta_ref = g_theta;        // latch current heading
				    g_e_theta_prev = 0.0f;
				}

				g_heading_hold_en = want_heading_hold;

				//Heading PD outer loop (run every 20 ms), then modify DesiredSpeed1/2
				float omega_corr = g_heading_omega_corr;

				if (g_heading_hold_en) {

				    g_heading_elapsed_s += (float)elapsed / configTICK_RATE_HZ;
				    // Run heading controller at slower rate
				    g_heading_div_ctr++;
				    if (g_heading_div_ctr >= HEADING_DIV) {
				        g_heading_div_ctr = 0;

				        float e_theta = wrap_pi(g_theta_ref - g_theta);
				        float de      = (g_heading_elapsed_s > 0.0f) ?
                            (e_theta - g_e_theta_prev) / g_heading_elapsed_s : 0.0f;

				        omega_corr = HEADING_KP * e_theta + HEADING_KD * de;
				        omega_corr = clampf(omega_corr, -OMEGA_CORR_MAX, OMEGA_CORR_MAX);

				        g_e_theta_prev = e_theta;
                        g_heading_elapsed_s = 0.0f;
                        g_heading_omega_corr = omega_corr;
                    }

				        // Convert omega correction -> wheel linear speed offsets
				        // vR = v + omega*L/2 ; vL = v - omega*L/2
				        float v_corr = omega_corr * (WHEEL_BASE_M * 0.5f);

				        // Keep same average command, just bias left/right
				        float v_avg = v_avg_cmd;

				        vR_ref_cmd = v_avg + v_corr;
				        vL_ref_cmd = v_avg - v_corr;

				} else {
				    g_heading_div_ctr = 0;
                    g_heading_omega_corr = 0.0f;
                    g_heading_elapsed_s = 0.0f;
				}

				DesiredSpeed2 = vL_ref_cmd;
				DesiredSpeed1 = vR_ref_cmd;
/////////////////////////////////////////////////////////////////////////////////////////////////
////////////////end of correct heading///////////////////////////////////////////////////////////

				//Here apply kick start if needed////////////////////////////////////////////
				float vL_cmd = DesiredSpeed2;
				float vR_cmd = DesiredSpeed1;

				// Replace these with your real measured wheel speeds used by PID inputs:
				float vL_meas = CurSpeed2;
				float vR_meas = CurSpeed1;

				apply_stiction_kick(&vL_cmd, &vR_cmd, vL_meas, vR_meas, dbg_motor_dt_ms);

				// Heading and kick must respect the existing wheel speed limit too.
				// Clamp before ramping so the acceleration bound still applies.
				DesiredSpeed2 = clampf(vL_cmd, -MAXSPEED, MAXSPEED);
				DesiredSpeed1 = clampf(vR_cmd, -MAXSPEED, MAXSPEED);
				//////////////////End of applying kick////////////////////////////////////////

				// ==========================================
				// BỔ SUNG: Áp dụng Velocity Ramping (Làm mượt gia tốc)
				// ==========================================

				Apply_Robot_RampingDt(&smoothed_speed1, DesiredSpeed1, ramp_dt);
				Apply_Robot_RampingDt(&smoothed_speed2, DesiredSpeed2, ramp_dt);

				// Gán ngược lại giá trị đã được làm mượt gia tốc vào biến đích cho PID
				DesiredSpeed1 = smoothed_speed1;
				DesiredSpeed2 = smoothed_speed2;
				// ==========================================

				uint32_t updated = PID_Compute(&SpeedPID1);
				updated |= (uint32_t)PID_Compute(&SpeedPID2) << 1;

				MotorData_Publish(SpeedPIDOut1, SpeedPIDOut2);  //update PWM data for LCD display

				Motor_SetSpeed(MOTOR_1,SpeedPIDOut1);
				Motor_SetSpeed(MOTOR_2,SpeedPIDOut2);
                if (!dbg_motor_trace_freeze) {
                    uint32_t n = dbg_motor_trace_write_count;
                    volatile MotorTrace *t = &dbg_motor_trace[n % 128U];
                    t->ms = step * portTICK_PERIOD_MS;
                    t->dt_ms = dbg_motor_dt_ms;
                    t->encoder_dt_ms = dbg_encoder_dt_ms;
                    t->cmd_count = dbg_cmd_cb_count;
                    t->cmd_age_ms = t->ms - last_cmdvel_ms;
                    t->gap_ms = dbg_cmd_gap_ms;
                    t->gap_max_ms = dbg_cmd_gap_max_ms;
                    t->gap_over_500ms = dbg_cmd_gap_over_500ms;
                    t->timeouts = num_timeout_ROScmd;
                    t->cmd_v = dbg_last_cmd_v; t->cmd_w = dbg_last_cmd_w;
                    t->raw1 = raw1; t->raw2 = raw2;
                    t->desired1 = DesiredSpeed1; t->desired2 = DesiredSpeed2;
                    t->measured1 = CurSpeed1; t->measured2 = CurSpeed2;
                    t->pwm1 = (int16_t)SpeedPIDOut1; t->pwm2 = (int16_t)SpeedPIDOut2;
                    t->pid_updated = updated; t->autonomous = autonomous_MODE;
                    __DMB();
                    t->sequence = n;
                    dbg_motor_trace_write_count = n + 1U;
                }

			}

			vTaskDelayUntil(&lastWake, period);
	    }
}

void OdometryTask(void *argument)
{
    const TickType_t period = pdMS_TO_TICKS(ODOMETRY_PERIOD_MS);
    TickType_t lastWake = xTaskGetTickCount();
    TickType_t lastTick = lastWake;

    for (;;)
    {
        TickType_t nowTick = xTaskGetTickCount();
        float dt = (float)(nowTick - lastTick) * (1.0f / configTICK_RATE_HZ);
        lastTick = nowTick;

        Odometry_Update(dt);
        OdomData_Publish(odom_x, odom_y, odom_theta);

        vTaskDelayUntil(&lastWake, period);
    }
}

void yaw_to_quaternion(float yaw, geometry_msgs__msg__Quaternion *q)
{
    q->x = 0.0;
    q->y = 0.0;
    q->z = sinf(yaw * 0.5f);
    q->w = cosf(yaw * 0.5f);
}

static bool microros_odom_init(rcl_node_t *node)
{
    odom_pub = rcl_get_zero_initialized_publisher();

    if (!nav_msgs__msg__Odometry__init(&odom_msg))
    {
        g_odom_msg_initialized = false;
        return false;
    }

    g_odom_msg_initialized = true;

    rcl_ret_t rc = rclc_publisher_init_default(
        &odom_pub,
        node,
        ROSIDL_GET_MSG_TYPE_SUPPORT(nav_msgs, msg, Odometry),
        "odomfromSTM32"
    );

    dbg_odom_init_rc = (int)rc;

    if (rc != RCL_RET_OK)
    {
        nav_msgs__msg__Odometry__fini(&odom_msg);

        g_odom_msg_initialized = false;
        g_odom_pub_initialized = false;

        return false;
    }

    // Bound reliable ACK waiting while g_uros_mutex is held. A long
    // default wait can stall both raw odometry and command reception.
    if (rmw_uros_set_publisher_session_timeout(rcl_publisher_get_rmw_handle(&odom_pub), 20) != RMW_RET_OK)
    {
        (void)rcl_publisher_fini(&odom_pub, node);
        nav_msgs__msg__Odometry__fini(&odom_msg);
        g_odom_msg_initialized = false;
        g_odom_pub_initialized = false;
        return false;
    }

    g_odom_pub_initialized = true;

    rosidl_runtime_c__String__assign(
        &odom_msg.header.frame_id,
        "odom"
    );

    rosidl_runtime_c__String__assign(
        &odom_msg.child_frame_id,
        "base_link"
    );

    return true;
}

static void microros_odom_fini(rcl_node_t *node)
{
    if (g_odom_pub_initialized)
    {
        (void)rcl_publisher_fini(
            &odom_pub,
            node
        );

        g_odom_pub_initialized = false;
    }

    if (g_odom_msg_initialized)
    {
        nav_msgs__msg__Odometry__fini(
            &odom_msg
        );

        g_odom_msg_initialized = false;
    }

    odom_pub = rcl_get_zero_initialized_publisher();

    memset(
        &odom_msg,
        0,
        sizeof(odom_msg)
    );
}

static void microros_publish_odom(void)
{
    int64_t now_ns = rmw_uros_epoch_nanos();

    odom_msg.header.stamp.sec =
        (int32_t)(now_ns / 1000000000LL);

    odom_msg.header.stamp.nanosec =
        (uint32_t)(now_ns % 1000000000LL);

    // pose
    odom_msg.pose.pose.position.x = odom_x;
    odom_msg.pose.pose.position.y = odom_y;
    odom_msg.pose.pose.position.z = 0.0f;

    yaw_to_quaternion(odom_theta, &odom_msg.pose.pose.orientation);

    // twist
    odom_msg.twist.twist.linear.x  = odom_vx;
    odom_msg.twist.twist.linear.y  = 0.0f;
    odom_msg.twist.twist.angular.z = odom_wz;

    rcl_ret_t rc = rcl_publish(&odom_pub, &odom_msg, NULL);

    if (rc == RCL_RET_OK) {
        odom_pub_fail_streak = 0;
    } else {
        odom_pub_fail_streak++;
        dbg_rcl_err_cnt++;
        //dbg_last_pub_rc = rc;
        if (odom_pub_fail_streak >= 5) {
            g_request_reconnect = true;
        }
        rcl_reset_error();
    }

//    if (rc != RCL_RET_OK) {
//        const rcl_error_string_t es = rcl_get_error_string();
//        // copy sang buffer để xem trong Debug Watch
//        size_t i = 0;
//        for (; i < sizeof(dbg_rcl_err)-1 && es.str[i] != '\0'; i++) {
//            dbg_rcl_err[i] = es.str[i];
//        }
//        dbg_rcl_err[i] = '\0';
//        dbg_rcl_err_cnt++;
//        rcl_reset_error();
//    }

//	if (rc != RCL_RET_OK) {
//		printf("[ODOM] rcl_publish failed rc=%d\n", (int)rc);
//	} else {
//		printf("[ODOM] ok\n");
//	}
}

static uint32_t millis_void(void)
{
	return (uint32_t)(xTaskGetTickCount() * portTICK_PERIOD_MS);
}

// ===== Callback /cmd_vel: publish raw ROS wheel commands =====
static void cmdvel_cb(const void * msgin)
{
	dbg_cmdvel_cb_cnt++;

    const geometry_msgs__msg__Twist *m = (const geometry_msgs__msg__Twist *) msgin;
    if (m == NULL) return;

    uint32_t now = millis_void();

	if (dbg_cmd_cb_count != 0U) {
		dbg_cmd_gap_ms = now - dbg_last_cmdvel_ms;
		if (dbg_cmd_gap_ms > dbg_cmd_gap_max_ms) {
			dbg_cmd_gap_max_ms = dbg_cmd_gap_ms;
		}
		if (dbg_cmd_gap_ms > 500U) {
			dbg_cmd_gap_over_500ms++;
		}
	}

	dbg_last_cmdvel_ms = now;
	dbg_cmd_cb_count++;
	dbg_last_cmd_v = m->linear.x;
	dbg_last_cmd_w = m->angular.z;

    float v = m->linear.x;   // m/s
    float w = m->angular.z;  // rad/s

    // --- tunables (start here) ---
    const float V_DEADBAND = 0.0005f;   // m/s  ignore tiny MPPI noise
    const float W_DEADBAND = 0.005f;    // rad/s

    const float V_MIN_EFF  = 0.05f;    // m/s  minimum that actually moves your robot
    const float W_MIN_EFF  = 0.25f;    // rad/s minimum rotate to break stiction

    // If MPPI asks to move/turn slightly, boost above stiction threshold
    v = apply_deadband_and_min(v, V_DEADBAND, V_MIN_EFF);
    w = apply_deadband_and_min(w, W_DEADBAND, W_MIN_EFF);

    // diff-drive: wheel linear speeds (m/s)
    float v_r = v + (w * WHEEL_BASE_M * 0.5f);
    float v_l = v - (w * WHEEL_BASE_M * 0.5f);

    taskENTER_CRITICAL();
    Spd1_cmdfromROS = v_l;
    Spd2_cmdfromROS = v_r;

    last_cmdvel_ms  = millis_void();
    autonomous_MODE = 1;
    taskEXIT_CRITICAL();

}

//hàm callback khi nhận được data PID từ ROS
static void pid_cb(const void * msgin)
{
    const std_msgs__msg__Float64MultiArray *m =
        (const std_msgs__msg__Float64MultiArray *)msgin;

    // cần đủ 6 phần tử
    if (m->data.size < 6) return;

    if (pid_mutex) xSemaphoreTake(pid_mutex, pdMS_TO_TICKS(2));

    Kp1 = m->data.data[0];
    Ki1 = m->data.data[1];
    Kd1 = m->data.data[2];
    Kp2 = m->data.data[3];
    Ki2 = m->data.data[4];
    Kd2 = m->data.data[5];

    pid_update_pending = 1;

    if (pid_mutex) xSemaphoreGive(pid_mutex);
}

//void MotionTask(void *argument)
//{
//	const TickType_t period = pdMS_TO_TICKS(MOTORCONTROL_PERIOD_MS);
//	TickType_t lastWake = xTaskGetTickCount();
//
//	MP_Config_t mp_cfg1, mp_cfg2;
//	MP_State_t  mp_state1, mp_state2;
//
//    mp_cfg1.dt      = DT_TIME;     // 5 ms
//    mp_cfg1.vmax    = MAXSPEED;   // your units
//    mp_cfg1.amax    = MAXACC;
//    mp_cfg1.vel_eps = 0.01f * MAXSPEED; // tune
//    mp_cfg1.pos_eps = 0.001f;          // tune (depends on units)
//
//    mp_cfg2.dt      = DT_TIME;     // 5 ms
//    mp_cfg2.vmax    = MAXSPEED;   // your units
//    mp_cfg2.amax    = MAXACC;
//    mp_cfg2.vel_eps = 0.01f * MAXSPEED; // tune
//    mp_cfg2.pos_eps = 0.001f;          // tune (depends on units)
//
//    // Initialize using current measured state:
//    MP_Init(&mp_state1, CurPos1, CurSpeed1);
//    MP_Init(&mp_state2, CurPos2, CurSpeed2);
//
//    int   prevMode = modCtrl;
//
//    float prevSetPos1 = SetPos1, prevSetPos2 = SetPos2;
//    float prevSetSpd1 = SetSpeed1, prevSetSpd2 = SetSpeed2;
//
//    for (;;)
//    {
//    	 // ---- Snapshot inputs (avoid reading changing globals mid-loop) ----
//    	int   mode = modCtrl;
//        float curPos1 = CurPos1, curPos2 = CurPos2;
//        float curSpd1 = CurSpeed1, curSpd2 = CurSpeed2;
//
//        float setPos1 = SetPos1, setPos2 = SetPos2;
//        float setSpd1 = SetSpeed1, setSpd2 = SetSpeed2;
//
//        // ---- Determine whether to re-seed planner state (ONE-TIME) ----
//        uint8_t modeChanged = (mode != prevMode);
//
//        uint8_t posCmdJump =
//            (fabsf_fast(setPos1 - prevSetPos1) > POS_CMD_RESYNC_TH) ||
//            (fabsf_fast(setPos2 - prevSetPos2) > POS_CMD_RESYNC_TH);
//
//        uint8_t spdCmdJump =
//            (fabsf_fast(setSpd1 - prevSetSpd1) > SPD_CMD_RESYNC_TH) ||
//            (fabsf_fast(setSpd2 - prevSetSpd2) > SPD_CMD_RESYNC_TH);
//
//        // Choose resync conditions based on mode
//        uint8_t needResync = modeChanged;
//
//        if (mode == MP_MODE_POSITION) {
//            needResync = needResync || posCmdJump;
//        } else {
//            needResync = needResync || spdCmdJump;
//        }
//
//        if (needResync) {
//            // Re-seed once from measured state so profile starts from reality
//            mp_state1.pos_ref = curPos1;
//            mp_state1.vel_ref = curSpd1;   // set to measured if your speed is OK; otherwise set to mp_state1.vel_ref
//            mp_state2.pos_ref = curPos2;
//            mp_state2.vel_ref = curSpd2;
//        }
//
//        // ---- Step profile ----
//        MP_Output_t ref1, ref2;
//
//        if (modCtrl == MP_MODE_POSITION) {
//        	ref1 = MP_StepPosition(&mp_cfg1, &mp_state1, setPos1);
//        	ref2 = MP_StepPosition(&mp_cfg2, &mp_state2, setPos2);
//            DesiredPos1 = ref1.pos_next;
//            DesiredPos2 = ref2.pos_next;
//        } else {
//        	ref1 = MP_StepVelocity(&mp_cfg1, &mp_state1, setSpd1);
//        	ref2 = MP_StepVelocity(&mp_cfg2, &mp_state2, setSpd2);
//            DesiredSpeed1 = ref1.vel_next;
//            DesiredSpeed2 = ref2.vel_next;
//        }
//
//        // ---- Save previous command/mode for next loop ----
//		prevMode = mode;
//		prevSetPos1 = setPos1;  prevSetPos2 = setPos2;
//		prevSetSpd1 = setSpd1;  prevSetSpd2 = setSpd2;
//
//        // v_ref goes into your PID controller later
//        // PID_Update(v_ref, measured_speed);
//
//        vTaskDelayUntil(&lastWake, period);
//    }
//}

void StartPS2Task(void *argument)
{
  TickType_t last = xTaskGetTickCount();
  const TickType_t period = pdMS_TO_TICKS(10);

  (void)argument;

  // Init library (HAL-based, not RTOS-aware)
  PS2X_Init(&ps2, &hspi2);

  // Configure controller: analog + rumble enabled
  bool cfg_ok = PS2X_ConfigGamepad(&ps2, true, true);

  for (;;)
  {
    // Poll controller
    bool ok = cfg_ok && PS2X_ReadGamepad(&ps2, 0, 0);

    // Build snapshot
    PS2X_State st;
    st.tick   = osKernelGetTickCount();
    st.ok     = ok ? 1 : 0;
    st.id     = ps2.id;
    st.buttons= ps2.buttons;
    st.analog = ps2.analog_enabled ? 1 : 0;
    st.rx     = ps2.analog[PSS_RX];
    st.ry     = ps2.analog[PSS_RY];
    st.lx     = ps2.analog[PSS_LX];
    st.ly     = ps2.analog[PSS_LY];

    // Publish snapshot for other tasks
    if (osMutexAcquire(g_ps2_mutex, 2) == osOK) {
      g_ps2_state = st;
      osMutexRelease(g_ps2_mutex);
    }

    // Poll period
    vTaskDelayUntil(&last, period);   // 10ms is typical; adjust if you want
  }
}

void StartTeleopTask(void *argument)
{
    (void)argument;

    for (;;)
    {
        // ---- snapshot controller state ----
        PS2X_State st;
        bool got = false;
        if (osMutexAcquire(g_ps2_mutex, 2) == osOK) {
            st = g_ps2_state;
            osMutexRelease(g_ps2_mutex);
            got = true;
        }

        // Use the SAME clock as last_cmdvel_ms
        uint32_t now_ms;

        // Default lock (manual path)
        float v_cmd = 0.0f;
        float w_cmd = 0.0f;
        bool enabled = false;

        taskENTER_CRITICAL();
        now_ms = millis_void();
        // ---- ROS cmd watchdog: if no cmd_vel -> force manual ----
        if (autonomous_MODE) {
            uint32_t age_ros = now_ms - last_cmdvel_ms;
            age_ros_check = age_ros;
            if (age_ros > CMDVEL_TIMEOUT_MS) {
                autonomous_MODE = 0;
                num_timeout_ROScmd = num_timeout_ROScmd + 1;
                // optional: clear ROS commands to avoid stale reuse
                //Spd1_cmdfromROS = 0.0f;
                //Spd2_cmdfromROS = 0.0f;
            }
        }

        // ===== NEW: If autonomous active -> move immediately (no L1 needed) =====
        if (autonomous_MODE) {
            float v_l = Spd1_cmdfromROS;  // left
            float v_r = Spd2_cmdfromROS;  // right

            // Optional clamp per wheel
            v_l = clampf(v_l, -V_MAX, +V_MAX);
            v_r = clampf(v_r, -V_MAX, +V_MAX);

            // Keep your mapping (as in your autonomous block)
            publish_motor_targets(v_r, v_l);
            taskEXIT_CRITICAL();

            osDelay(10);
            continue; // bypass manual logic below
        }

        taskEXIT_CRITICAL();

        // ---- decide enable (L1) and manual commands ----
        if (got && st.ok) {
            // timeout check for PS2
            uint32_t age = osKernelGetTickCount() - st.tick;
            if (age <= PS2_TIMEOUT_MS) {

                // L1 enable (manual only now)
                if (is_pressed(st.buttons, PSB_L1)) {
                    enabled = true;

                    // ===== Manual mode: keep your existing logic =====
                    int16_t rx = (int16_t)st.rx - 128;
                    int16_t ry = (int16_t)st.ry - 128;

                    if (abs(rx) < STICK_DEADBAND) rx = 0;
                    if (abs(ry) < STICK_DEADBAND) ry = 0;

                    bool analog_active = (rx != 0) || (ry != 0);

                    if (analog_active) {
                        float rx_n = (float)rx / 127.0f;      // -1..1
                        float ry_n = (float)ry / 127.0f;      // -1..1

                        v_cmd = (-ry_n) * V_MAX;
                        w_cmd = ( rx_n) * W_MAX;

                    } else {
                        bool up    = is_pressed(st.buttons, PSB_UP);
                        bool down  = is_pressed(st.buttons, PSB_DOWN);
                        bool left  = is_pressed(st.buttons, PSB_LEFT);
                        bool right = is_pressed(st.buttons, PSB_RIGHT);

                        if (up && !down && !left && !right) {
                            v_cmd = +V_STEP;  w_cmd = 0.0f;
                        } else if (down && !up && !left && !right) {
                            v_cmd = -V_STEP;  w_cmd = 0.0f;
                        } else if (left && !up && !down && !right) {
                            v_cmd = 0.0f;     w_cmd = -W_STEP;
                        } else if (right && !up && !down && !left) {
                            v_cmd = 0.0f;     w_cmd = +W_STEP;
                        } else {
                            v_cmd = 0.0f;     w_cmd = 0.0f;
                        }
                    }
                }
            }
        }

        // If not enabled or timeout => lock (0,0)
        if (!enabled) {
            v_cmd = 0.0f;
            w_cmd = 0.0f;
        }

        // ---- convert cmd_vel to wheel linear speeds (manual path only) ----
        float v_r = v_cmd + (w_cmd * WHEEL_BASE_M * 0.5f);
        float v_l = v_cmd - (w_cmd * WHEEL_BASE_M * 0.5f);

        v_r = clampf(v_r, -V_MAX, +V_MAX);
        v_l = clampf(v_l, -V_MAX, +V_MAX);

        // Preserve the existing manual mapping; verify physically before changing.
        publish_motor_targets(v_l, v_r);

        osDelay(10);
    }
}

static inline void EncData_Publish(int32_t enc1, int32_t enc2, float v1, float v2, float v1d, float v2d)
{
  g_encSeq++; __DMB();
  g_encData.enc1 = enc1;
  g_encData.enc2 = enc2;
  g_encData.v1   = v1;
  g_encData.v2   = v2;
  g_encData.v1d = v1d;
  g_encData.v2d = v2d;
  __DMB(); g_encSeq++;
}

static inline void OdomData_Publish(float x, float y, float yaw)
{
  g_odomSeq++; __DMB();
  g_odomData.x   = x;
  g_odomData.y   = y;
  g_odomData.yaw = yaw;
  __DMB(); g_odomSeq++;
}

static inline void MotorData_Publish(float pwm1, float pwm2)
{
  g_motorSeq++; __DMB();
  g_motorData.pwm1 = pwm1;
  g_motorData.pwm2 = pwm2;
  __DMB(); g_motorSeq++;
}

static inline void EncData_Read(EncData_t* out)
{
  uint32_t s1, s2;
  do {
    s1 = g_encSeq; __DMB();
    *out = g_encData; __DMB();
    s2 = g_encSeq;
  } while ((s1 != s2) || (s1 & 1u));
}

static inline void OdomData_Read(OdomData_t* out)
{
  uint32_t s1, s2;
  do {
    s1 = g_odomSeq; __DMB();
    *out = g_odomData; __DMB();
    s2 = g_odomSeq;
  } while ((s1 != s2) || (s1 & 1u));
}

static inline void MotorData_Read(MotorData_t* out)
{
  uint32_t s1, s2;
  do {
    s1 = g_motorSeq; __DMB();
    *out = g_motorData; __DMB();
    s2 = g_motorSeq;
  } while ((s1 != s2) || (s1 & 1u));
}

void StartLCDTask(void *argument)
{
  TickType_t last = xTaskGetTickCount();
  const TickType_t period = pdMS_TO_TICKS(10);

  lcdInit();
  lcdSetOrientation(LCD_ORIENTATION_LANDSCAPE);

  UI_InitAndDrawOnce();
//  UI_LoadPIDFromFlashOnce();   // ✅ CHỈ LOAD 1 LẦN Ở ĐÂY (ngoài loop)

  static uint32_t t_ui = 0;

  for(;;)
  {
    uint16_t tx = g_touchState.x;
    uint16_t ty = g_touchState.y;
    uint8_t  p  = g_touchState.pressed ? 1 : 0;

    uint16_t x = (ty <= 319) ? (uint16_t)(319 - ty) : 0;
    uint16_t y = (tx <= 239) ? (uint16_t)(239 - tx) : 0;

    UI_OnTouch(x, y, p);

    if (HAL_GetTick() - t_ui > 100) {
      t_ui = HAL_GetTick();

      UI_UpdateEncoderPage(g_encData.enc1, g_encData.enc2,
                           g_encData.v1, g_encData.v2,
                           g_encData.v1d, g_encData.v2d,
                           g_motorData.pwm1, g_motorData.pwm2);

      if (UI_GetActivePage() == UI_PAGE_5) {
          Graph_Push(g_encData.v1, g_encData.v2, g_encData.v1d, g_encData.v2d);
          UI_VelGraph_UpdateCurvesOnly();
      }

      UI_UpdatePIDPage();   // ✅ GIỮ LẠI
      UI_UpdateOdomPage(g_odomData.x, g_odomData.y, g_odomData.yaw);

      }

    }

  vTaskDelayUntil(&last, period);
}

void vApplicationStackOverflowHook(TaskHandle_t xTask, char *pcTaskName)
{
  (void)xTask;
  printf("STACK OVERFLOW: %s\r\n", pcTaskName);
  taskDISABLE_INTERRUPTS();
  for(;;);
}

void StartMicroRosRxTask(void *argument)
{
    (void)argument;

    const uint64_t spin_timeout_ns = 1ULL * 1000000ULL; // 1 ms
    uint32_t last_tick = osKernelGetTickCount();
    const uint32_t period_ms = 10U; // 100 Hz

    for (;;)
    {
        if (!g_uros_connected || g_request_reconnect)
        {
            osDelay(20);
            last_tick = osKernelGetTickCount();
            continue;
        }

        if (osMutexAcquire(g_uros_mutex, 5) == osOK)
        {
            rcl_ret_t rc = rclc_executor_spin_some(&g_executor, spin_timeout_ns);
            osMutexRelease(g_uros_mutex);

            if (rc != RCL_RET_OK && rc != RCL_RET_TIMEOUT)
            {
                dbg_rx_spin_err_cnt++;
                g_request_reconnect = true;
            }
        }

        uint32_t now = osKernelGetTickCount();
        uint32_t elapsed = now - last_tick;
        if (elapsed < period_ms)
        {
            osDelay(period_ms - elapsed);
        }
        last_tick = osKernelGetTickCount();
    }
}

void StartMicroRosOdomPubTask(void *argument)
{
    (void)argument;

    uint32_t last_tick = osKernelGetTickCount();
    const uint32_t period_ms = 10U;   // 100 Hz
    // const uint32_t period_ms = 20U; // 50 Hz
    // const uint32_t period_ms = 33U; // ~30 Hz

    for (;;)
    {
        if (!g_uros_connected || g_request_reconnect)
        {
            osDelay(20);
            last_tick = osKernelGetTickCount();
            continue;
        }

        if (osMutexAcquire(g_uros_mutex, 10) == osOK)
        {
            microros_publish_odom();
            dbg_pub_odom_cnt++;
            osMutexRelease(g_uros_mutex);
        }

        uint32_t now = osKernelGetTickCount();
        uint32_t elapsed = now - last_tick;
        if (elapsed < period_ms)
        {
            osDelay(period_ms - elapsed);
        }
        last_tick = osKernelGetTickCount();
    }
}
/* USER CODE END Application */
